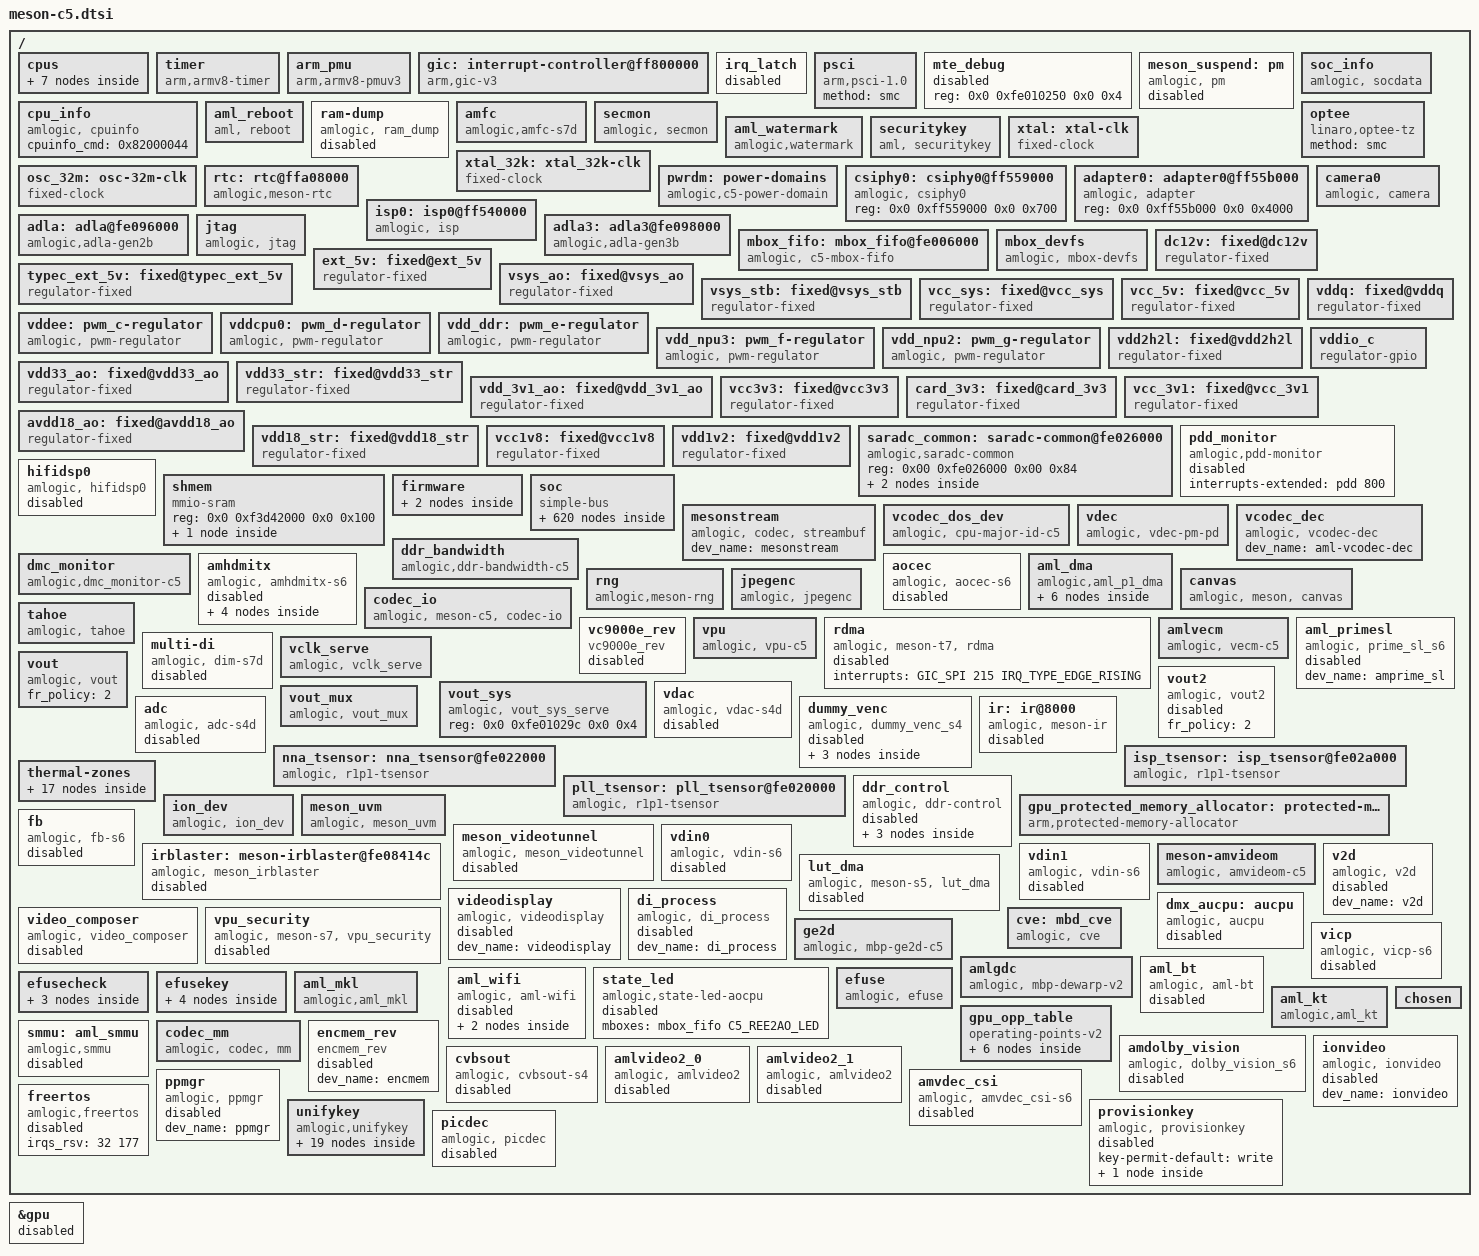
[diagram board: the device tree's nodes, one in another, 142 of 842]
// SPDX-License-Identifier: (GPL-2.0+ OR MIT)
/*
 * Copyright (c) 2019 Amlogic, Inc. All rights reserved.
 */

#include <dt-bindings/clock/axg-audio-clkc.h>
#include <dt-bindings/clock/amlogic,c5-clkc.h>
#include <dt-bindings/clock/amlogic,c5-scmi-clkc.h>
#include <dt-bindings/clock/g12a-aoclkc.h>
#include <dt-bindings/interrupt-controller/irq.h>
#include <dt-bindings/interrupt-controller/arm-gic.h>
#include <dt-bindings/power/c5-pd.h>
#include <dt-bindings/gpio/gpio.h>
#include <dt-bindings/gpio/meson-c5-gpio.h>
#include <dt-bindings/reset/amlogic,meson-c5-reset.h>
#include <dt-bindings/pwm/pwm.h>
#include <dt-bindings/pwm/meson.h>
#include <dt-bindings/input/input.h>
#include <dt-bindings/input/meson_ir.h>
#include <dt-bindings/mailbox/amlogic,mbox.h>
#include <dt-bindings/firmware/amlogic,firmware.h>
#include <dt-bindings/mailbox/c5-mbox.h>
#include <dt-bindings/iio/adc/amlogic-saradc.h>
#include <dt-bindings/thermal/ddr-params.h>
#include "meson-ir-map.dtsi"
#include "meson-valhall.dtsi"
/ {
	cpus:cpus {
		#address-cells = <2>;
		#size-cells = <0>;

		CPU0:cpu@0 {
			device_type = "cpu";
			compatible = "arm,cortex-a320","arm,armv9";
			reg = <0x0 0x0>;
			enable-method = "psci";
			cpu-idle-states = <&CPU_SLEEP_0 &SYSTEM_SLEEP_0>;
			dynamic-power-coefficient = <230>;
			#cooling-cells = <2>;
		};

		CPU1:cpu@1 {
			device_type = "cpu";
			compatible = "arm,cortex-a320","arm,armv9";
			reg = <0x0 0x100>;
			enable-method = "psci";
			cpu-idle-states = <&CPU_SLEEP_0 &SYSTEM_SLEEP_0>;
			dynamic-power-coefficient = <230>;
			#cooling-cells = <2>;
		};

		CPU2:cpu@2 {
			device_type = "cpu";
			compatible = "arm,cortex-a320","arm,armv9";
			reg = <0x0 0x200>;
			enable-method = "psci";
			cpu-idle-states = <&CPU_SLEEP_0 &SYSTEM_SLEEP_0>;
			dynamic-power-coefficient = <230>;
			#cooling-cells = <2>;
		};

		CPU3:cpu@3 {
			device_type = "cpu";
			compatible = "arm,cortex-a320","arm,armv9";
			reg = <0x0 0x300>;
			enable-method = "psci";
			cpu-idle-states = <&CPU_SLEEP_0 &SYSTEM_SLEEP_0>;
			dynamic-power-coefficient = <230>;
			#cooling-cells = <2>;
		};
		idle-states {
			entry-method = "arm,psci-0.2";
			CPU_SLEEP_0: cpu-sleep-0 {
					/*compatible = "arm,idle-state";*/
					arm,psci-suspend-param = <0x0010000>;
					local-timer-stop;
					entry-latency-us = <100>;
					exit-latency-us = <234>;
					min-residency-us = <1212>;
			};
			SYSTEM_SLEEP_0: system-sleep-0 {
					/*compatible = "arm,idle-state";*/
					arm,psci-suspend-param = <0x0000000>;
					entry-latency-us = <0x3fffffff>;
					exit-latency-us = <0x40000000>;
					min-residency-us = <0xffffffff>;
			};
		};
	};

	timer {
		compatible = "arm,armv8-timer";
		interrupts = <GIC_PPI 13 0xff08>,
				<GIC_PPI 14 0xff08>,
				<GIC_PPI 11 0xff08>,
				<GIC_PPI 10 0xff08>;
	};

	arm_pmu {
		compatible = "arm,armv8-pmuv3";
		/*private-interrupts;*/

		interrupts = <GIC_SPI 300 IRQ_TYPE_LEVEL_HIGH>,
				<GIC_SPI 301 IRQ_TYPE_LEVEL_HIGH>,
				<GIC_SPI 302 IRQ_TYPE_LEVEL_HIGH>,
				<GIC_SPI 303 IRQ_TYPE_LEVEL_HIGH>;
	};

	gic: interrupt-controller@ff800000 {
		compatible = "arm,gic-v3";
		#interrupt-cells = <3>;
		#address-cells = <0>;
		interrupt-controller;
		reg = <0x0 0xff800000 0 0x10000>,
		      <0x0 0xff840000 0 0x80000>;
		interrupts = <GIC_PPI 9 0xf04>;
	};

	irq_latch {
		/* only for GICv3 */
		status = "disabled";
		reg = <0x0 0xfe00a140 0x0 0x30>, /*mode*/
			<0x0 0xfe00a1c0 0x0 0x30>; /*latch clear*/
	};

	psci {
		compatible = "arm,psci-1.0";
		method = "smc";
	};

	mte_debug {
		status = "disabled";
		reg = <0x0 0xfe010250 0x0 0x4>; /*SYSCTRL_DEBUG_REG4*/
	};

	meson_suspend:pm {
		compatible = "amlogic, pm";
		status = "disabled";
		device_name = "aml_pm";
		extend_resume_reason;
		clear_suspend_reason = <9>; /* Clear netflix wakeup reason */
		reg = <0x0 0xfe010288 0x0 0x4>, /*SYSCTRL_STATUS_REG2*/
			<0x0 0xfe0102dc 0x0 0x4>; /*SYSCTRL_STICKY_REG7*/
	};

	cpu_info {
		compatible = "amlogic, cpuinfo";
		status = "okay";
		cpuinfo_cmd = <0x82000044>;
	};

	soc_info {
		compatible = "amlogic, socdata";
		reg =	<0x0 0xfe010000 0x0 0xc>,
			<0x0 0xfe010180 0x0 0x4>;
		read_nocsdata_cmd =<0x82000039>;
		write_nocsdata_cmd=<0x82000038>;
		auth_reg_ops_cmd=<0x820000f0>;
	};

	aml_reboot {
		compatible = "aml, reboot";
		sys_reset = <0x84000009>;
		sys_poweroff = <0x84000008>;
		dis_nb_cpus_in_shutdown;
		extend_reboot_reason; /* Support up to 128 reboot reasons*/
		reg = <0x0 0xfe01037c 0x0 0x4>; /* SEC_AO_SEC_SD_CFG15 */
		status = "okay";
	};

	ram-dump {
		compatible = "amlogic, ram_dump";
		status = "disabled";
		reg = <0x0 0xFE0102D8 0x0 4>;
		reg-names = "SYSCTRL_STICKY_REG6";
		store_device = "data";
	};

	amfc {
		compatible = "amlogic,amfc-s7d";
		status = "okay";
		/* registers and clk */
		reg = <0x0 0xfe024000 0x0 0x200
		       0x0 0xfe000000 0x0 0x400>;
		interrupts = <0 185 IRQ_TYPE_EDGE_RISING
			      0 186 IRQ_TYPE_EDGE_RISING>;
		interrupt-names = "amfc0", "amfc1";
		power-domains=<&pwrdm PDID_C5_AMFC>;
		clocks = <&clkc CLKID_AMFC>;
		assigned-clocks = <&clkc CLKID_AMFC>;
		assigned-clock-rates = <666666666>;
	};

	secmon:secmon {
		compatible = "amlogic, secmon";
		memory-region = <&secmon_reserved>;
		in_base_func = <0x82000020>;
		out_base_func = <0x82000021>;
		inout_size_func = <0x8200002a>;
		reserve_mem_size = <0x03300000>;
	};

	optee {
		compatible = "linaro,optee-tz";
		method = "smc";
	};

	aml_watermark {
		compatible = "amlogic,watermark";
		soc-name = "s6";
		interrupts = <GIC_SPI 197 IRQ_TYPE_EDGE_RISING>; //=viu-vsync
		interrupt-names = "wm-vsync";
	};

	securitykey {
		compatible = "aml, securitykey";
		storage_query = <0x82000060>;
		storage_read = <0x82000061>;
		storage_write = <0x82000062>;
		storage_tell = <0x82000063>;
		storage_verify = <0x82000064>;
		storage_status = <0x82000065>;
		storage_list = <0x82000067>;
		storage_remove = <0x82000068>;
		storage_in_func = <0x82000023>;
		storage_out_func = <0x82000024>;
		storage_block_func = <0x82000025>;
		storage_size_func = <0x82000027>;
		storage_set_enctype = <0x8200006A>;
		storage_get_enctype = <0x8200006B>;
		storage_version = <0x8200006C>;
	};

	xtal: xtal-clk {
		compatible = "fixed-clock";
		clock-frequency = <24000000>;
		clock-output-names = "xtal";
		#clock-cells = <0>;
	};

	xtal_32k: xtal_32k-clk {
		compatible = "fixed-clock";
		clock-frequency = <32768>;
		clock-output-names = "xtal_32k";
		#clock-cells = <0>;
	};

	osc_32m: osc-32m-clk {
		compatible = "fixed-clock";
		clock-frequency = <32000000>;
		clock-output-names = "osc_32m";
		#clock-cells = <0>;
	};

	rtc: rtc@ffa08000 {
		compatible = "amlogic,meson-rtc";
		reg = <0x0 0xffa08000 0x0 0x38>;
		interrupts = <GIC_SPI 404 IRQ_TYPE_EDGE_RISING>;
		clocks = <&ao_clkc CLKID_AO_OSCIN32K_CLK>,
			 <&ao_clkc CLKID_AO_SYS_RTC_DIG>;
		clock-names = "osc", "sys";
		time-storage-format-gray;
		status = "okay";
		assigned-clocks = <&ao_clkc CLKID_AO_OSCIN32K_CLK>;
		assigned-clock-parents = <&xtal_32k>;
	};

	pwrdm: power-domains {
		compatible = "amlogic,c5-power-domain";
		#power-domain-cells = <1>;
		status = "okay";
	};

	csiphy0: csiphy0@ff559000 {
		compatible = "amlogic, csiphy0";
		reg = <0x0 0xff559000 0x0 0x700>;
		//clocks = <&clkc CLKID_CSIPHY0>;
		clock-names = "mipi_phy_clk";
		reg-names = "csi_phy0";
		status = "okay";
	};

	adapter0: adapter0@ff55b000 {
		compatible = "amlogic, adapter";
		reg = <0x0 0xff55b000 0x0 0x4000>;
		reg-names = "adapter";
		status = "okay";
	};

	isp0: isp0@ff540000 {
		compatible = "amlogic, isp";
		reg = <0x0 0xff540000 0x0 0x17780>,
				<0x0 0xff566000 0x0 0x600>;
		reg-names = "base", "disp";
		power-domains = <&pwrdm PDID_C5_ISP>,<&pwrdm PDID_C5_DEWARP>;
		power-domain-names = "isp_pd", "opp_pd";
		clocks = <&clkc CLKID_CSIPHY0>, <&clkc CLKID_ISP0>, <&clkc CLKID_DEWARPA>;
		clock-names = "mipi_csi_clk", "mipi_isp_clk", "isp_dewarp_clk";
		interrupts = <GIC_SPI 383 IRQ_TYPE_EDGE_RISING>,
			     <GIC_SPI 372 IRQ_TYPE_EDGE_RISING>,
			     <GIC_SPI 373 IRQ_TYPE_EDGE_RISING>,
			     <GIC_SPI 374 IRQ_TYPE_EDGE_RISING>,
			     <GIC_SPI 379 IRQ_TYPE_EDGE_RISING>,
			     <GIC_SPI 380 IRQ_TYPE_EDGE_RISING>;
		interrupt-names = "fe_rst", "fe_done", "be_done",
				  "opp_done", "mipi_top", "intf";
		status = "okay";
	};

	camera0 {
		compatible = "amlogic, camera";
		index = <0>;
		csiphy = <&csiphy0>;
		adapter = <&adapter0>;
		isp = <&isp0>;
		status = "okay";
	};

	adla: adla@fe096000 {
		compatible = "amlogic,adla-gen2b";
		dev_name = "adla";
		status = "okay";
		reg = <0x0 0xfe096000 0x0 0x2000
			0x0 0xf3d00000 0x0 0x15FFFF
			>;
		reg-names = "adla_reg\0adla_sram";
		interrupt-names = "adla";
		interrupts = <GIC_SPI 258 IRQ_TYPE_LEVEL_HIGH>;
		clocks = <&clkc CLKID_NNA2_CORE>;
		clock-names = "adla_core_clk";
		power-domains=<&pwrdm PDID_C5_NNA2>;
		nn_hw_version="r3p3";
		adla_core_clk_rate = <1000000000>;
		adla_smc_cmd = <0x820000b2>;
		smmu;
	};

	adla3: adla3@fe098000 {
		compatible = "amlogic,adla-gen3b";
		dev_name = "adla";
		status = "okay";
		reg = <0x0 0xfe098000 0x0 0x2000
			0x0 0xf3d00000 0x0 0x15FFFF
			>;
		reg-names = "adla_reg\0adla_sram";
		interrupt-names = "adla";
		interrupts = <GIC_SPI 260 IRQ_TYPE_LEVEL_HIGH>;
		clocks = <&clkc CLKID_NNA_CORE>;
		clock-names = "adla_core_clk";
		power-domains=<&pwrdm PDID_C5_NNA3>;
		nn_hw_version="r4p2";
		adla_core_clk_rate = <1000000000>;
		adla_smc_cmd = <0x820000b2>;
		smmu;
	};

	jtag {
		compatible = "amlogic, jtag";
		status = "okay";
		select = "disable"; /* disable/jtag_a/jtag_b */
		pinctrl-names="jtag_a_pins", "jtag_b_pins";
		pinctrl-0=<&jtag_a_pins>;
		pinctrl-1=<&jtag_b_pins>;
	};

	mbox_fifo: mbox_fifo@fe006000 {
		status = "okay";
		compatible = "amlogic, c5-mbox-fifo";
		reg = <0x0 0xfe006000 0x0 0x800>,  /* mbox wr fifo */
		      <0x0 0xfe006800 0x0 0x800>,  /* mbox rd fifo */
		      <0x0 0xfe0070c0 0x0 0x40>,   /* mbox set reg */
		      <0x0 0xfe007100 0x0 0x40>,   /* mbox clr reg */
		      <0x0 0xfe007140 0x0 0x40>,   /* mbox sts reg */
		      <0x0 0xfe007020 0x0 0x40>;   /* mbox irqctrl reg */
		interrupts = <GIC_SPI 248 IRQ_TYPE_EDGE_RISING>;   /* mbox top irq */
		mbox-irqctlr = <0>;
		mbox-nums = <C5_MBOX_NUMS>;
		mboxids = <C5_MBOX_AO2REE>,
			  <C5_MBOX_REE2AO>;
		aocpu_sts_mboxid = <C5_MBOX_AO2TEE>;
		ree2aocpu_mboxid = <C5_MBOX_REE2AO>;
		#mbox-cells = <1>;
	};

	mbox_devfs {
		status = "okay";
		compatible = "amlogic, mbox-devfs";
		mbox-nums = <2>;
		mbox-names = "ree2aocpu",
			     "aocpu2ree";
		mboxes = <&mbox_fifo C5_REE2AO_DEV>,
			 <&mbox_fifo C5_AO2REE_DEV>;
		mbox-dests = <MAILBOX_AOCPU>,
			     <MAILBOX_ARM>;
	};

	dc12v: fixed@dc12v {
		compatible = "regulator-fixed";
		regulator-name = "DC12V";
		regulator-min-microvolt = <12000000>;
		regulator-max-microvolt = <12000000>;
		regulator-boot-on;
		regulator-always-on;
	};

	ext_5v: fixed@ext_5v { //to charger ic
		compatible = "regulator-fixed";
		vin-supply = <&dc12v>;
		regulator-name = "EXT_5V";
		regulator-min-microvolt = <5000000>;
		regulator-max-microvolt = <5000000>;
		regulator-boot-on;
		regulator-always-on;
	};

	typec_ext_5v: fixed@typec_ext_5v {
		compatible = "regulator-fixed";
		vin-supply = <&ext_5v>;
		regulator-name = "TYPEC_5V_EXT";
		regulator-min-microvolt = <5000000>;
		regulator-max-microvolt = <5000000>;
		regulator-boot-on;
		regulator-always-on;
	};

	vsys_ao: fixed@vsys_ao { //charger ic out
		compatible = "regulator-fixed";
		vin-supply = <&ext_5v>;
		regulator-name = "VSYS_AO";
		regulator-min-microvolt = <5000000>;
		regulator-max-microvolt = <5000000>;
		regulator-boot-on;
		regulator-always-on;
	};

	//Power ON/OFF for Debug Test
	vsys_stb: fixed@vsys_stb { //Slide_Switch_PWR
		compatible = "regulator-fixed";
		vin-supply = <&vsys_ao>;
		regulator-name = "VSYS_STB";
		regulator-min-microvolt = <5000000>;
		regulator-max-microvolt = <5000000>;
		regulator-boot-on;
		regulator-always-on;
	};

	vcc_sys: fixed@vcc_sys {
		compatible = "regulator-fixed";
		vin-supply = <&vsys_stb>;
		regulator-name = "VCC_SYS";
		regulator-min-microvolt = <5000000>;
		regulator-max-microvolt = <5000000>;
		//PWR_UP to PWR_EE_CTRL
		gpio = <&gpio_ao GPIOAO_24 GPIO_ACTIVE_HIGH>;
		startup-delay-us = <7000>;
		enable-active-high;
		regulator-boot-on;
		regulator-always-on;
	};

	vcc_5v: fixed@vcc_5v {
		compatible = "regulator-fixed";
		vin-supply = <&vcc_sys>;
		regulator-name = "Boost VCC_5V";
		regulator-min-microvolt = <5000000>;
		regulator-max-microvolt = <5000000>;
		regulator-boot-on;
		regulator-always-on;
	};

	vddee: pwm_c-regulator {
		compatible = "amlogic, pwm-regulator";
		vin-supply = <&vcc_sys>;
		pwms = <&pwm_c MESON_PWM_0 630 0>;//GPIOE_0
		regulator-name = "VDD_EE";
		regulator-min-microvolt = <680000>;
		regulator-max-microvolt = <830000>;
		regulator-always-on;
		max-duty-cycle = <630>;
		amlogic,vsel-step = <3>;
		amlogic,usleep-time = <200>;
		amlogic,udelay-time = <40 20>;//pwm 1nF
		/* Voltage Duty-Cycle */
		voltage-table = <830000 0>,
				<820000 7>,
				<810000 13>,
				<800000 20>,
				<790000 27>,
				<780000 33>,
				<770000 40>,
				<760000 47>,
				<750000 53>,
				<740000 60>,
				<730000 67>,
				<720000 73>,
				<710000 80>,
				<700000 87>,
				<690000 93>,
				<680000 100>;
		status = "okay";
	};

	vddcpu0: pwm_d-regulator {
		compatible = "amlogic, pwm-regulator";
		vin-supply = <&vcc_sys>;
		pwms = <&pwm_d MESON_PWM_0 1260 0>;//GPIOE_1
		regulator-name = "VDDCPU_A320";
		regulator-min-microvolt = <680000>;
		regulator-max-microvolt = <980000>;
		regulator-always-on;
		max-duty-cycle = <1260>;
		amlogic,vsel-step = <3>;
		amlogic,usleep-time = <200>;
		amlogic,udelay-time = <40 20>;	//pwm 1nF
		/* Voltage Duty-Cycle */
		voltage-table = <980000 0>,
				<970000 3>,
				<960000 7>,
				<950000 10>,
				<940000 13>,
				<930000 17>,
				<920000 20>,
				<910000 23>,
				<900000 27>,
				<890000 30>,
				<880000 33>,
				<870000 37>,
				<860000 40>,
				<850000 43>,
				<840000 47>,
				<830000 50>,
				<820000 53>,
				<810000 57>,
				<800000 60>,
				<790000 63>,
				<780000 67>,
				<770000 70>,
				<760000 73>,
				<750000 77>,
				<740000 80>,
				<730000 83>,
				<720000 87>,
				<710000 90>,
				<700000 93>,
				<690000 97>,
				<680000 100>;
		status = "okay";
	};

	vdd_ddr: pwm_e-regulator {
		compatible = "amlogic, pwm-regulator";
		vin-supply = <&vcc_sys>;
		pwms = <&pwm_e MESON_PWM_0 630 0>;//GPIOE_2
		regulator-name = "VDD_DDR";
		regulator-min-microvolt = <680000>;
		regulator-max-microvolt = <830000>;
		regulator-always-on;
		max-duty-cycle = <630>;
		amlogic,vsel-step = <3>;
		amlogic,usleep-time = <200>;
		amlogic,udelay-time = <40 20>;//pwm 1nF
		/* Voltage Duty-Cycle */
		voltage-table = <830000 0>,
				<820000 7>,
				<810000 13>,
				<800000 20>,
				<790000 27>,
				<780000 33>,
				<770000 40>,
				<760000 47>,
				<750000 53>,
				<740000 60>,
				<730000 67>,
				<720000 73>,
				<710000 80>,
				<700000 87>,
				<690000 93>,
				<680000 100>;
		status = "okay";
	};

	vdd_npu3: pwm_f-regulator {
		compatible = "amlogic, pwm-regulator";
		vin-supply = <&vcc_sys>;
		pwms = <&pwm_f MESON_PWM_0 840 0>;//GPIOE_3
		regulator-name = "VDD_NPU3";
		regulator-min-microvolt = <660000>;
		regulator-max-microvolt = <860000>;
		regulator-always-on;
		max-duty-cycle = <840>;
		amlogic,vsel-step = <3>;
		amlogic,usleep-time = <200>;
		amlogic,udelay-time = <40 20>;//pwm 1nF
		/* Voltage Duty-Cycle */
		voltage-table = <860000 0>,
				<850000 5>,
				<840000 10>,
				<830000 15>,
				<820000 20>,
				<810000 25>,
				<800000 30>,
				<790000 35>,
				<780000 40>,
				<770000 45>,
				<760000 50>,
				<750000 55>,
				<740000 60>,
				<730000 65>,
				<720000 70>,
				<710000 75>,
				<700000 80>,
				<690000 85>,
				<680000 90>,
				<670000 95>,
				<660000 100>;
		status = "okay";
	};

	vdd_npu2: pwm_g-regulator {
		compatible = "amlogic, pwm-regulator";
		vin-supply = <&vcc_sys>;
		pwms = <&pwm_g MESON_PWM_0 840 0>;//GPIOE_4
		regulator-name = "VDD_NPU2";
		regulator-min-microvolt = <660000>;
		regulator-max-microvolt = <860000>;
		regulator-always-on;
		max-duty-cycle = <840>;
		amlogic,vsel-step = <3>;
		amlogic,usleep-time = <200>;
		amlogic,udelay-time = <40 20>;//pwm 1nF
		/* Voltage Duty-Cycle */
		voltage-table = <860000 0>,
				<850000 5>,
				<840000 10>,
				<830000 15>,
				<820000 20>,
				<810000 25>,
				<800000 30>,
				<790000 35>,
				<780000 40>,
				<770000 45>,
				<760000 50>,
				<750000 55>,
				<740000 60>,
				<730000 65>,
				<720000 70>,
				<710000 75>,
				<700000 80>,
				<690000 85>,
				<680000 90>,
				<670000 95>,
				<660000 100>;
		status = "okay";
	};

	vddq: fixed@vddq { //Option
		compatible = "regulator-fixed";
		vin-supply = <&vsys_stb>;
		regulator-name = "VDDQ";
		regulator-min-microvolt = <500000>;
		regulator-max-microvolt = <500000>;
		//STR_EN
		gpio = <&gpio_ao GPIOAO_16 GPIO_ACTIVE_HIGH>;
		startup-delay-us = <7000>;
		enable-active-high;
		regulator-boot-on;
		regulator-always-on;
	};

	vdd2h2l: fixed@vdd2h2l { //Option
		compatible = "regulator-fixed";
		vin-supply = <&vsys_stb>;
		regulator-name = "VDD2H/VDD2L";
		regulator-min-microvolt = <1050000>;
		regulator-max-microvolt = <1050000>;
		//STR_EN
		gpio = <&gpio_ao GPIOAO_16 GPIO_ACTIVE_HIGH>;
		startup-delay-us = <7000>;
		enable-active-high;
		regulator-boot-on;
		regulator-always-on;
	};

	vdd33_ao: fixed@vdd33_ao {
		compatible = "regulator-fixed";
		vin-supply = <&vsys_stb>;
		regulator-name = "VDD33_AO";
		regulator-min-microvolt = <3300000>;
		regulator-max-microvolt = <3300000>;
		regulator-boot-on;
		regulator-always-on;
	};

	vdd33_str: fixed@vdd33_str { //Only needed in the AOV camera scenario.
		compatible = "regulator-fixed";
		vin-supply = <&vdd33_ao>;
		regulator-name = "VDD33_STR";
		regulator-min-microvolt = <3300000>;
		regulator-max-microvolt = <3300000>;
		//STR_EN
		gpio = <&gpio_ao GPIOAO_16 GPIO_ACTIVE_HIGH>;
		startup-delay-us = <7000>;
		enable-active-high;
		regulator-boot-on;
		regulator-always-on;
	};

	vdd_3v1_ao: fixed@vdd_3v1_ao { //Option 3.1V
		compatible = "regulator-fixed";
		vin-supply = <&vdd33_ao>;
		regulator-name = "VDD_3V1_AO";
		regulator-min-microvolt = <3100000>;
		regulator-max-microvolt = <3100000>;
		regulator-boot-on;
		regulator-always-on;
	};

	vcc3v3: fixed@vcc3v3 {
		compatible = "regulator-fixed";
		vin-supply = <&vdd33_ao>;
		regulator-name = "VCC3V3";
		regulator-min-microvolt = <3300000>;
		regulator-max-microvolt = <3300000>;
		//VDD33_CTRL
		gpio = <&gpio_ao GPIOAO_25 GPIO_ACTIVE_HIGH>;
		startup-delay-us = <7000>;
		enable-active-high;
		regulator-boot-on;
		regulator-always-on;
	};

	card_3v3: fixed@card_3v3 {
		compatible = "regulator-fixed";
		vin-supply = <&vcc3v3>;
		regulator-name = "3V3_CARD";
		regulator-min-microvolt = <3300000>;
		regulator-max-microvolt = <3300000>;
		//SD_PWR_EN
		gpio = <&gpio GPIOC_7 (GPIO_ACTIVE_HIGH | GPIO_OPEN_DRAIN)>;
		startup-delay-us = <7000>;
		enable-active-high;
		regulator-boot-on;
		regulator-always-on;
	};

	vddio_c: vddio_c {
		compatible = "regulator-gpio";
		vin-supply = <&vcc3v3>;
		regulator-name = "VDDIO_C";
		regulator-min-microvolt = <1800000>;
		regulator-max-microvolt = <3300000>;
		//L=3.3V H=1.8V (GPIOE_6 (HiZ)(PWM_I))
		gpio = <&gpio GPIOE_6 GPIO_ACTIVE_HIGH>;
		gpios-states = <0>;
		states = <1800000 1 3300000 0>;
		startup-delay-us = <7000>;
		regulator-boot-on;
		//regulator-always-on;
	};

	vcc_3v1: fixed@vcc_3v1 { //Option 3.1V
		compatible = "regulator-fixed";
		vin-supply = <&vcc3v3>;
		regulator-name = "VCC_3V1";
		regulator-min-microvolt = <3100000>;
		regulator-max-microvolt = <3100000>;
		regulator-boot-on;
		regulator-always-on;
	};

	avdd18_ao: fixed@avdd18_ao {
		compatible = "regulator-fixed";
		vin-supply = <&vsys_stb>;
		regulator-name = "AVDD18_AO";
		regulator-min-microvolt = <1800000>;
		regulator-max-microvolt = <1800000>;
		regulator-boot-on;
		regulator-always-on;
	};

	vdd18_str: fixed@vdd18_str { //Only needed in the AOV camera scenario.
		compatible = "regulator-fixed";
		vin-supply = <&avdd18_ao>;
		regulator-name = "VDD18_STR";
		regulator-min-microvolt = <1800000>;
		regulator-max-microvolt = <1800000>;
		//STR_EN
		gpio = <&gpio_ao GPIOAO_16 GPIO_ACTIVE_HIGH>;
		startup-delay-us = <7000>;
		enable-active-high;
		regulator-boot-on;
		regulator-always-on;
	};

	vcc1v8: fixed@vcc1v8 {
		compatible = "regulator-fixed";
		vin-supply = <&avdd18_ao>;
		regulator-name = "VCC1V8";
		regulator-min-microvolt = <1800000>;
		regulator-max-microvolt = <1800000>;
		//VDD18_CTRL
		gpio = <&gpio_ao GPIOAO_23 GPIO_ACTIVE_HIGH>;
		startup-delay-us = <7000>;
		enable-active-high;
		regulator-boot-on;
		regulator-always-on;
	};

	vdd1v2: fixed@vdd1v2 { //Option: Removable if Not use PSRAM
		compatible = "regulator-fixed";
		vin-supply = <&vsys_stb>;
		regulator-name = "VDD1V2";
		regulator-min-microvolt = <1200000>;
		regulator-max-microvolt = <1200000>;
		regulator-boot-on;
		regulator-always-on;
	};

	saradc_common: saradc-common@fe026000 {
		compatible = "amlogic,saradc-common";
		reg = <0x00 0xfe026000 0x00 0x84>;

		saradc: saradc {
			compatible = "amlogic,saradc", "amlogic,s7d-saradc";
			interrupts = <GIC_SPI 181 IRQ_TYPE_EDGE_RISING>;
			//clock-names = "src", "core", "gate", "mux";
			//clocks = <&xtal>,
			//	 <&clkc CLKID_SYS_SAR_ADC>,
			//	 <&clkc CLKID_SAR_ADC>,
			//	 <&clkc CLKID_SAR_ADC_MUX>;
			#io-channel-cells = <1>;
			amlogic,clock-frequency = <3000000>;
			amlogic,test-channel = <7>;
			amlogic,fifo-data-width = <16>;
			/* Filter control */
			amlogic,reg7-init = <0x00000c11>;
			amlogic,reg8-init = <0x0280614d>;
			/* Delay configure */
			amlogic,reg3-init = <0x10a02403>;
			amlogic,reg4-init = <0x001dd080>;
			/* Set aux and external vref */
			amlogic,reg9-init = <0x0000f0f0>;
			amlogic,reg10-init = <0x70503010>;
			amlogic,reg11-init = <0xf0d0b090>;
			reset-names = "analog";
			//resets = <&reset RESET_SAR_ANA>;
			status = "disabled";
		};

		pdd: pdd {
			compatible = "amlogic,pdd";
			interrupt-controller;
			#interrupt-cells = <1>;
			//clock-names = "core";
			//clocks = <&clkc CLKID_SYS_SAR_ADC>;
			amlogic,interrupt = <182>;
			amlogic,digital-maps = <0x18 26>, <0x18 23>, <0x18 17>,
					       <0x18 12>, <0x18 14>;
			amlogic,analog-maps = <0x14 26>, <0x14 22>, <0x14 24>;
			amlogic,voltage-maps = <400>, <800>, <800>, <1200>;
			status = "disabled";
		};
	};

	pdd_monitor {
		compatible = "amlogic,pdd-monitor";
		/* Trigger threshold voltage: 800 mV */
		interrupts-extended = <&pdd 800>;
		status = "disabled";
	};

	hifidsp0: hifidsp0 {
		compatible = "amlogic, hifidsp0";
		status = "disabled";
		startup-position = /bits/ 8 <PURE_DDR>; /*host dsp start mode : DDR*/
		memory-region = <&dsp_fw_reserved>;
		reg-names = "base-reg",
			    "health-reg",
			    "device-support-reg",
			    "ddrfw-region",
			    "shm-region";
		reg = <0x0 0xfe380000 0x0 0x114>, /*host base address*/
		      <0x0 0xfe010258 0x0 0x4>, /*host health reg address*/
		      <0x0 0xfe44006c 0x0 0x4>, /*dsp support region*/
		      <0x0 0x0 0x0 0x800000>, /*host ddrfw region [offset size]*/
		      <0x0 0x780000 0x0 0x80000>; /*host shm region [offset size]*/
		//assigned-clocks = <&scmi_clk CLKID_GP2_PLL>;
		//assigned-clock-rates = <1002000000>;
		//clocks = <&clkc CLKID_DSPA>,
		//	 <&clkc CLKID_HIFI_PLL>;
		//clock-names = "dspa_clk",
		//	      "dspa_clk_hifi";
		/* host dsp support bit
		 * efuse reg OTP_LIC23 bit[24]
		 * 1: disable
		 * 0: enable
		 */
		dsp-support-bit = <0x1000000>;
		/* bit0: pm_support_suspend
		 * bit1: pm_support_always_on
		 * bit2: pm_support_ffv
		 */
		pm-support = /bits/ 8 <0x5>;
		//power-domains = <&pwrdm PDID_S6_DSPA>;
		power-domain-names = "dspa";
		mboxes = <&mbox_fifo C5_REE2DSPA_HOST>,
			 <&mbox_fifo C5_DSPA2REE_HOST>;
		//logbuff-polling-ms = <50>;
		health-polling-ms = <1000>;
		clkfreq-khz = <1002000>;
	};

	shmem {
		compatible = "mmio-sram";
		reg = <0x0 0xf3d42000 0x0 0x100>;
		#address-cells = <1>;
		#size-cells = <1>;
		ranges = <0 0x0 0xf3d42000 0x100>;

		scmi_shmem: shmem@0 {
			compatible = "arm,scmi-shmem";
			reg = <0x0 0x100>;
		};
	};

	firmware {
		scmi: scmi {
			compatible = "arm,scmi-smc";
			arm,smc-id = <0x820000C1>;
			shmem = <&scmi_shmem>;
			#address-cells = <1>;
			#size-cells = <0>;

			scmi_clk: protocol@14 {
				reg = <0x14>;
				#clock-cells = <1>;
			};
		};
	};

	soc {
		compatible = "simple-bus";
		#address-cells = <2>;
		#size-cells = <2>;
		ranges;

		apb4: apb4@fe000000 {
			compatible = "simple-bus";
			reg = <0x0 0xfe000000 0x0 0x480000>;
			#address-cells = <2>;
			#size-cells = <2>;
			ranges = <0x0 0x0 0x0 0xfe000000 0x0 0x480000>;

			clkc: clock-controller@0 {
				compatible = "amlogic,c5-clkc";
				#clock-cells = <1>;
				reg = <0x0 0x0 0x0 0x4a0>,
				      <0x0 0x8000 0x0 0x38c>;
				reg-names = "basic", "pll";
				clocks = <&xtal>,
					 <&scmi_clk CLKID_GP0_PLL_OSC>,
					 <&scmi_clk CLKID_HIFI_PLL_OSC>,
					 <&scmi_clk CLKID_DSI_PLL_OSC>,
					 <&scmi_clk CLKID_FIXED_PLL>,
					 <&scmi_clk CLKID_SYS_CLK>,
					 <&scmi_clk CLKID_AXI_CLK>,
					 <&scmi_clk CLKID_SYS_PLL_DIV16>,
					 <&scmi_clk CLKID_CPU_CLK_DIV16>;
				clock-names = "xtal",
					      "gp0_pll_osc",
					      "hifi_pll_osc",
					      "dsi_pll_osc",
					      "fixed_pll",
					      "sys_clk",
					      "axi_clk",
					      "sys_pll_div16",
					      "cpu_clk_div16";
				status = "okay";
			};

			meson_clk_msr@48000 {
				compatible = "amlogic,meson-c5-clk-measure";
				reg = <0x0 0x48000 0x0 0x1c>;
			};

			watchdog@2100 {
				compatible = "amlogic,meson-sc2-wdt";
				/* 0:userspace, 1:kernel */
				amlogic,feed_watchdog_mode = <1>;
				reg = <0x0 0x2100 0x0 0x10>;
				clocks = <&xtal>;
			};

			periphs_pinctrl: pinctrl@4000 {
				compatible = "amlogic,meson-c5-periphs-pinctrl";
				#address-cells = <2>;
				#size-cells = <2>;
				ranges;

				gpio: bank@4000 {
					reg = <0x0 0x4000 0x0 0x004c>,
					      <0x0 0x40c0 0x0 0x0260>;
					reg-names = "mux", "gpio";
					gpio-controller;
					#gpio-cells = <2>;
					gpio-ranges = <&periphs_pinctrl 0 0 109>;
				};
			};

			gpio_intc: interrupt-controller@4080 {
				compatible = "amlogic,meson-c5-gpio-intc",
					     "amlogic,meson-gpio-intc";
				reg = <0x0 0x4080 0x0 0x20>;
				interrupt-controller;
				#interrupt-cells = <2>;
				amlogic,channel-interrupts =
					<10 11 12 13 14 15 16 17 18 19 20 21>;
			};

			spisg_b: spi@50000 {
				compatible = "amlogic,meson-t6x-spicc-v2";
				reg = <0x0 0x50000 0x0 0x38>;
				interrupts = <GIC_SPI 183 IRQ_TYPE_LEVEL_HIGH>;
				clocks = <&clkc CLKID_SYS_SPISG0>,
					 <&clkc CLKID_SPISG0>;
				clock-names = "sys", "spi";
				assigned-clocks = <&clkc CLKID_SPISG0>;
				assigned-clock-rates = <500000000>;
				#address-cells = <1>;
				#size-cells = <0>;
				status = "disabled";
			};

			spisg_c: spi@50100 {
				compatible = "amlogic,meson-t6x-spicc-v2";
				reg = <0x0 0x50100 0x0 0x38>;
				interrupts = <GIC_SPI 184 IRQ_TYPE_LEVEL_HIGH>;
				clocks = <&clkc CLKID_SYS_SPISG0>,
					 <&clkc CLKID_SPISG1>;
				clock-names = "sys", "spi";
				assigned-clocks = <&clkc CLKID_SPISG1>;
				assigned-clock-rates = <500000000>;
				#address-cells = <1>;
				#size-cells = <0>;
				status = "disabled";
			};

			spisg_d: spi@50200 {
				compatible = "amlogic,meson-t6x-spicc-v2";
				reg = <0x0 0x50200 0x0 0x38>;
				interrupts = <GIC_SPI 187 IRQ_TYPE_LEVEL_HIGH>;
				clocks = <&clkc CLKID_SYS_SPISG0>,
					 <&clkc CLKID_SPISG2>;
				clock-names = "sys", "spi";
				assigned-clocks = <&clkc CLKID_SPISG2>;
				assigned-clock-rates = <500000000>;
				#address-cells = <1>;
				#size-cells = <0>;
				status = "disabled";
			};

			spifc: spi@56000 {
				compatible = "amlogic,meson-spifc";
				status = "disabled";
				reg = <0x0 0x56000 0x0 0x80>;
				//clock-names = "default";
				//clocks = <&clkc CLKID_SPIFC>;
				pinctrl-names = "default";
				pinctrl-0 = <&spifc_pins>;
				#address-cells = <1>;
				#size-cells = <0>;
				spi-nor@0 {
					compatible = "jedec,spi-nor";
					status = "disabled";
					reg = <0>;
					spi-max-frequency = <16000000>;
				};
			};

			pwm_c: pwm@58000 {
				compatible = "amlogic,meson-pwm-tee";
				reg = <0x0  0x58000 0x0 0x24>;
				#pwm-cells = <3>;
				clocks = <&clkc CLKID_PWM_C>;
				clock-names = "clkin0";
				tee_id = <2>;
				status = "okay";
				pinctrl-names="default";
				pinctrl-0=<&pwm_c_pins1>;
			};

			pwm_d: pwm@58100 {
				compatible = "amlogic,meson-pwm-tee";
				reg = <0x0 0x58100 0x0 0x24>;
				#pwm-cells = <3>;
				clocks = <&clkc CLKID_PWM_D>;
				clock-names = "clkin0";
				tee_id = <3>;
				status = "okay";
				pinctrl-names="default";
				pinctrl-0=<&pwm_d_pins1>;
			};

			pwm_e: pwm@58200 {
				compatible = "amlogic,meson-pwm-tee";
				reg = <0x0 0x58200 0x0 0x24>;
				#pwm-cells = <3>;
				clocks = <&clkc CLKID_PWM_E>;
				clock-names = "clkin0";
				tee_id = <4>;
				status = "okay";
				pinctrl-names="default";
				pinctrl-0=<&pwm_e_pins1>;
			};

			pwm_f: pwm@58300 {
				compatible = "amlogic,meson-pwm-tee";
				reg = <0x0 0x58300 0x0 0x24>;
				#pwm-cells = <3>;
				clocks = <&clkc CLKID_PWM_F>;
				clock-names = "clkin0";
				tee_id = <5>;
				status = "okay";
				pinctrl-names="default";
				pinctrl-0=<&pwm_f_pins1>;
			};

			pwm_g: pwm@58400 {
				compatible = "amlogic,meson-pwm-tee";
				reg = <0x0  0x58400 0x0 0x24>;
				#pwm-cells = <3>;
				clocks = <&clkc CLKID_PWM_G>;
				clock-names = "clkin0";
				tee_id = <6>;
				status = "okay";
				pinctrl-names="default";
				pinctrl-0=<&pwm_g_pins1>;
			};

			pwm_h: pwm@58500 {
				compatible = "amlogic,meson-pwm-tee";
				reg = <0x0 0x58500 0x0 0x24>;
				#pwm-cells = <3>;
				clocks = <&clkc CLKID_PWM_H>;
				clock-names = "clkin0";
				tee_id = <7>;
				status = "okay";
				pinctrl-names="default";
				pinctrl-0=<&pwm_h_pins1>;
			};

			pwm_i: pwm@58600 {
				compatible = "amlogic,meson-pwm-tee";
				reg = <0x0 0x58600 0x0 0x24>;
				#pwm-cells = <3>;
				clocks = <&clkc CLKID_PWM_I>;
				clock-names = "clkin0";
				tee_id = <8>;
				status = "disabled";
			};

			pwm_j: pwm@58700 {
				compatible = "amlogic,meson-pwm-tee";
				reg = <0x0 0x58700 0x0 0x24>;
				#pwm-cells = <3>;
				clocks = <&clkc CLKID_PWM_J>;
				clock-names = "clkin0";
				tee_id = <9>;
				status = "okay";
				pinctrl-names="default";
				pinctrl-0=<&pwm_j_pins1>;
			};

			pwm_k: pwm@58800 {
				compatible = "amlogic,meson-pwm-tee";
				reg = <0x0  0x58800 0x0 0x24>;
				#pwm-cells = <3>;
				clocks = <&clkc CLKID_PWM_K>;
				clock-names = "clkin0";
				tee_id = <10>;
				status = "disabled";
			};

			pwm_l: pwm@58900 {
				compatible = "amlogic,meson-pwm-tee";
				reg = <0x0 0x58900 0x0 0x24>;
				#pwm-cells = <3>;
				clocks = <&clkc CLKID_PWM_L>;
				clock-names = "clkin0";
				tee_id = <11>;
				status = "disabled";
			};

			pwm_m: pwm@58a00 {
				compatible = "amlogic,meson-pwm-tee";
				reg = <0x0 0x58a00 0x0 0x24>;
				#pwm-cells = <3>;
				clocks = <&clkc CLKID_PWM_M>;
				clock-names = "clkin0";
				tee_id = <12>;
				status = "disabled";
			};

			pwm_n: pwm@58b00 {
				compatible = "amlogic,meson-pwm-tee";
				reg = <0x0 0x58b00 0x0 0x24>;
				#pwm-cells = <3>;
				clocks = <&clkc CLKID_PWM_N>;
				clock-names = "clkin0";
				tee_id = <13>;
				status = "disabled";
			};

			pwm_o: pwm@58c00 {
				compatible = "amlogic,meson-pwm-tee";
				reg = <0x0  0x58c00 0x0 0x24>;
				#pwm-cells = <3>;
				clocks = <&clkc CLKID_PWM_O>;
				clock-names = "clkin0";
				tee_id = <14>;
				status = "disabled";
			};

			pwm_p: pwm@58d00 {
				compatible = "amlogic,meson-pwm-tee";
				reg = <0x0 0x58d00 0x0 0x24>;
				#pwm-cells = <3>;
				clocks = <&clkc CLKID_PWM_P>;
				clock-names = "clkin0";
				tee_id = <15>;
				status = "disabled";
			};

			pwm_q: pwm@58e00 {
				compatible = "amlogic,meson-pwm-tee";
				reg = <0x0 0x58e00 0x0 0x24>;
				#pwm-cells = <3>;
				clocks = <&clkc CLKID_PWM_Q>;
				clock-names = "clkin0";
				tee_id = <16>;
				status = "disabled";
			};

			pwm_r: pwm@58f00 {
				compatible = "amlogic,meson-pwm-tee";
				reg = <0x0 0x58f00 0x0 0x24>;
				#pwm-cells = <3>;
				clocks = <&clkc CLKID_PWM_R>;
				clock-names = "clkin0";
				tee_id = <17>;
				status = "disabled";
			};

			pwm_s: pwm@59000 {
				compatible = "amlogic,meson-pwm-tee";
				reg = <0x0 0x59000 0x0 0x24>;
				#pwm-cells = <3>;
				clocks = <&clkc CLKID_PWM_S>;
				clock-names = "clkin0";
				tee_id = <18>;
				status = "disabled";
			};

			pwm_t: pwm@59100 {
				compatible = "amlogic,meson-pwm-tee";
				reg = <0x0 0x59100 0x0 0x24>;
				#pwm-cells = <3>;
				clocks = <&clkc CLKID_PWM_T>;
				clock-names = "clkin0";
				tee_id = <19>;
				status = "disabled";
			};

			i2c2: i2c@3a4000 {
				compatible = "amlogic,meson-i2c-v2-1";
				reg = <0x0 0x3a4000 0x0 0x3c>;
				interrupts = <GIC_SPI 162 IRQ_TYPE_EDGE_RISING>;
				#address-cells = <1>;
				#size-cells = <0>;
				clocks = <&clkc CLKID_SYS_I2C_M_C>;
				status = "disabled";
			};

			i2c3: i2c@3a4100 {
				compatible = "amlogic,meson-i2c-v2-1";
				reg = <0x0 0x3a4100 0x0 0x3c>;
				interrupts = <GIC_SPI 163 IRQ_TYPE_EDGE_RISING>;
				#address-cells = <1>;
				#size-cells = <0>;
				clocks = <&clkc CLKID_SYS_I2C_M_D>;
				status = "disabled";
			};

			i2c4: i2c@3a4200 {
				compatible = "amlogic,meson-i2c-v2-1";
				reg = <0x0 0x3a4200 0x0 0x3c>;
				interrupts = <GIC_SPI 164 IRQ_TYPE_EDGE_RISING>;
				#address-cells = <1>;
				#size-cells = <0>;
				clocks = <&clkc CLKID_SYS_I2C_M_E>;
				status = "disabled";
			};

			i2c5: i2c@3a4300 {
				compatible = "amlogic,meson-i2c-v2-1";
				reg = <0x0 0x3a4300 0x0 0x3c>;
				interrupts = <GIC_SPI 165 IRQ_TYPE_EDGE_RISING>;
				#address-cells = <1>;
				#size-cells = <0>;
				clocks = <&clkc CLKID_SYS_I2C_M_F>;
				status = "disabled";
			};

			i2c6: i2c@3a4400 {
				compatible = "amlogic,meson-i2c-v2-1";
				reg = <0x0 0x3a4400 0x0 0x3c>;
				interrupts = <GIC_SPI 166 IRQ_TYPE_EDGE_RISING>;
				#address-cells = <1>;
				#size-cells = <0>;
				clocks = <&clkc CLKID_SYS_I2C_M_G>;
				status = "disabled";
			};

			reset: reset-controller@2000 {
				compatible = "amlogic,meson-t7-reset";
				reg = <0x0 0x2000 0x0 0x98>;
				#reset-cells = <1>;
			};

			cpu_version {
				compatible = "amlogic,meson-gx-ao-secure", "syscon";
				reg=<0x0 0x10220 0x0 0x4>;
			};
		};

		aobus: bus@ffa00000 {
			compatible = "simple-bus";
			reg = <0x0 0xffa00000 0x0 0x100000>;
			#address-cells = <2>;
			#size-cells = <2>;
			ranges = <0x0 0x0 0x0 0xffa00000 0x0 0x100000>;

			ao_clkc: clock-controller@1 {
				compatible = "amlogic,c5-aoclkc";
				reg = <0x0 0x0 0x0 0x5c>;
				reg-names = "basic";
				#clock-cells = <1>;
				clocks = <&xtal>,
					<&xtal_32k>,
					<&osc_32m>,
					<&scmi_clk CLKID_SYS_CLK>,
					<&clkc CLKID_FCLK_DIV5>,
					<&clkc CLKID_FCLK_DIV4>,
					<&clkc CLKID_FCLK_DIV3>;
				clock-names = "xtal",
					      "xtal_32k",
					      "osc_32m",
					      "sys_clk",
					      "fclk_div5",
					      "fclk_div4",
					      "fclk_div3";
				status = "okay";
			};

			ao_pwm_a: pwm@10000 {
				compatible = "amlogic,meson-pwm-tee";
				reg = <0x0  0x10000 0x0 0x24>;
				#pwm-cells = <3>;
				clocks = <&clkc CLKID_AO_PWM_A>;
				clock-names = "clkin0";
				tee_id = <0>;
				status = "disabled";
			};

			ao_pwm_b: pwm@10200 {
				compatible = "amlogic,meson-pwm-tee";
				reg = <0x0 0x10200 0x0 0x24>;
				#pwm-cells = <3>;
				clocks = <&clkc CLKID_AO_PWM_B>;
				clock-names = "clkin0";
				tee_id = <1>;
				status = "disabled";
			};

			uart_AO_B: serial@1e000 {
				compatible = "amlogic,meson-uart";
				reg = <0x0 0x1e000 0x0 0x18>;
				interrupts = <GIC_SPI 64 IRQ_TYPE_EDGE_RISING>;
				status = "okay";
				clocks = <&xtal>;
				clock-names = "clk_uart";
				xtal_tick_en = <2>;
				fifosize = < 64 >;
				/* 0 not support; 1 support */
				support-sysrq = <1>;
			};

			uart_AO_A: serial@1a000 {
				compatible = "amlogic,meson-uart";
				reg = <0x0 0x1a000 0x0 0x18>;
				interrupts = <GIC_SPI 415 IRQ_TYPE_EDGE_RISING>;
				status = "disabled";
				clocks = <&xtal
					&clkc CLKID_AO_SYS_UART_A>;
				clock-names = "clk_uart", "clk_gate";
				fifosize = < 64 >;
				pinctrl-names = "default";
				pinctrl-0 = <&ao_a_uart_pins>;
			};

			ao_pinctrl: ao_pinctrl@4000 {
				compatible = "amlogic,meson-c5-ao-pinctrl";
				#address-cells = <2>;
				#size-cells = <2>;
				ranges;
				amlogic,ao-interrupt-controller;

				gpio_ao: ao-bank@4000 {
					reg = <0x0 0x4000 0x0 0x0020>,
					      <0x0 0x4080 0x0 0x0120>;
					reg-names = "mux", "gpio";
					gpio-controller;
					#gpio-cells = <2>;
					gpio-ranges = <&ao_pinctrl 0 0 48>;
				};
			};

			gpio_ao_intc: interrupt-controller@4040 {
				compatible = "amlogic,meson-c5-gpio-ao-intc",
					     "amlogic,meson-gpio-ao-intc";
				reg = <0x0 0x4040 0x0 0x30>;
				interrupt-controller;
				#interrupt-cells = <2>;
				amlogic,channel-interrupts =
					<384 385 386 387 388 389 390 391 392
					 393 394 395 396 397 398 399 400 401
					 402 403 >;
			};

			i2c0: i2c@e000 {
				compatible = "amlogic,meson-i2c-v2-1";
				reg = <0x0 0xe000 0x0 0x3c>;
				interrupts = <GIC_SPI 408 IRQ_TYPE_EDGE_RISING>;
				#address-cells = <1>;
				#size-cells = <0>;
				clocks = <&ao_clkc CLKID_AO_SYS_I2C_M_A>;
				status = "disabled";
			};

			i2c1: i2c@e100 {
				compatible = "amlogic,meson-i2c-v2-1";
				reg = <0x0 0xe100 0x0 0x3c>;
				interrupts = <GIC_SPI 409 IRQ_TYPE_EDGE_RISING>;
				#address-cells = <1>;
				#size-cells = <0>;
				clocks = <&ao_clkc CLKID_AO_SYS_I2C_M_B>;
				status = "disabled";
			};

			ao_reset: ao-reset-controller@2000 {
				compatible = "amlogic,meson-a9-ao-reset";
				reg = <0x0 0x2000 0x0 0xc>;
				#reset-cells = <1>;
			};
		};

		usbphy0: usbphy0@fe310000 {
			compatible = "amlogic,uphy-c5";
			#address-cells = <1>;
			#size-cells = <1>;
			status = "disabled";
			u2p0port0: u2p@0 {
				#phy-cells = <0>;
				port-speed = <0x0>; /* 0~2: HS HSP SS */
				reg = <0xfe310000 0x10
						0xfe002000 0x100
						0xfe010330 0x4
						0xfe314000 0x60>;
				reset-level = <0x40>;
				phy-reset-level-bits = <4>;
				usb-comb-reset-bit = <6>;
				phy-apb-reset-bit = <7>;
				pll-settings = <0x0
								0x0
								0x0
								0x7e18
								0x7>;
				interrupts = <0 139 IRQ_TYPE_EDGE_RISING>;
				clocks = <&clkc CLKID_SYS_USB_U3DRD>;
				clock-names = "sys_usb3";
				power-domains = <&pwrdm PDID_C5_USB3>;
			};

			u3p0port0: u3p@80 {
				#phy-cells = <0>;
				port-speed = <0x3>; /* 0~2: HS HSP SS */
				reg = <0xfe310080 0x20		/* phy3 cfg base */
						0xfe002000 0x100	/* reset base */
						0xfe312000 0x184	/* phy3 ctrl base */
						0xfe01034c 0x4>;	/* phy3 trim base */
				usb3-phy-reset-bit = /bits/ 8 <0x3>;
				usb3-apb-reset-bit = /bits/ 8 <0x2>;
				usb3-controller-reset-bit = /bits/ 8 <0x5>;
				reset-level-shift = <0x40>;
				clocks = <&clkc CLKID_SYS_USB_U3DRD>;
				clock-names = "sys_usb3";
				//pll-sw-cfg;
			};
		};

		usbphy1: usbphy1@fe300000 {
			compatible = "amlogic,uphy-c5";
			#address-cells = <1>;
			#size-cells = <1>;
			status = "disabled";
			u2p1port0: u2p@0 {
				#phy-cells = <0>;
				port-speed = <0x0>; /* 0~2: HS HSP SS */
				reg = <0xfe300000 0x10
						0xfe002000 0x100
						0xfe010330 0x4
						0xfe302000 0x60>;
				reset-level = <0x40>;
				phy-reset-level-bits = <0xb>;
				usb-comb-reset-bit = <0x9>;
				phy-apb-reset-bit = <0xa>;
				pll-settings = <0x0
								0x0
								0x0
								0x7e18
								0x7>;
				clocks = <&clkc CLKID_SYS_USB_U2H>;
				clock-names = "usb_general";
				power-domains = <&pwrdm PDID_C5_USB2>;
			};

		};

		dwc3otg1: dwc3otg1@0xfe310000{
			status = "disable";
			compatible = "amlogic,dwc3-meson-drd";
			reg = <0x0 0xfe310000 0x0 0x100>;
			phys = <&u2p0port0>;
			phy-names = "usb2-phy";
			interrupts = <GIC_SPI 139 IRQ_TYPE_EDGE_RISING>;
			ports {
				#address-cells = <1>;
				#size-cells = <0>;
				port@0 {
					reg = <0>;
					usb_otg1_ep: endpoint {
						remote-endpoint = <&usba_role_switch>;
					};
				};
			};
		};

		dwc3a: dwc3a@f3f00000 {
			status = "disable";
			compatible = "snps,dwc3-meson";
			maximum-speed = "super-speed";
			dr_mode = "host"; /*using role control mode, this must be otg*/
			//dr_mode = "peripheral";
			phy_type = "utmi";
			reg = <0x0 0xf3f00000 0x0 0x10000>;
			interrupts = <GIC_SPI 140 IRQ_TYPE_LEVEL_HIGH>;
			interrupt-names = "dwc_usb3";
			clocks = <&clkc CLKID_SYS_USB_U3DRD>, <&xtal>, <&xtal>;
			clock-names = "bus_early", "ref", "suspend";
			phys = <&u2p0port0>, <&u3p0port0>;
			phy-names = "usb2-phy", "usb3-phy";
			power-domains = <&pwrdm PDID_C5_USB3>;
			//resets = <&reset RESET_U3DRD>;
			snps,usb2-lpm-disable;
			//snps,usb3_lpm_capable;
			snps,usb2-gadget-lpm-disable;
			snps,has-lpm-erratum;
			/* better try */
			//snps,rx_detect_poll_quirk;
			snps,dis_u3_susphy_quirk;
			snps,dis_u2_susphy_quirk;
			snps,dis_enblslpm_quirk;
			/* why we do this? dwc3_ref_clk_period() */
			/* must enable GFLADJ_REFCLK_LPM_SEL */
			//snps,dis-u2-freeclk-exists-quirk;
			//snps,gfladj-refclk-lpm-sel-quirk;
			/* need post-silicon test. */
			//snps,quirk-frame-length-adjustment;
			snps,rx-thr-num-pkt = <2>;
			snps,rx-max-burst = <16>;
			snps,tx-thr-num-pkt = <2>;
			snps,tx-max-burst = <16>;
			tx-fifo-resize;
			tx-fifo-max-num = <3>;
			snps,incr-burst-type-adjustment = <4>;
			usb-role-switch;

			ports {
				#address-cells = <1>;
				#size-cells = <0>;
				port@0 {
					reg = <0>;
					usba_role_switch: endpoint {
						remote-endpoint = <&usb_otg1_ep>;
					};
				};
			};
		};

		dwc3otg2: dwc3otg2@0xfe300000{
			status = "disable";
			compatible = "amlogic,dwc3-meson-drd";
			reg = <0x0 0xfe300000 0x0 0x100>;
			phys = <&u2p1port0>;
			phy-names = "usb2-phy";
			interrupts = <GIC_SPI 139 IRQ_TYPE_EDGE_RISING>;
			ports {
				#address-cells = <1>;
				#size-cells = <0>;
				port@0 {
					reg = <0>;
					usb_otg2_ep: endpoint {
						remote-endpoint = <&usbb_role_switch>;
					};
				};
			};
		};

		dwc3b: dwc3b@f3c80000 {
			status = "disable";
			compatible = "snps,dwc3-meson";
			maximum-speed = "super-speed";
			dr_mode = "otg"; /*using role control mode, this must be otg*/
			//dr_mode = "peripheral";
			phy_type = "utmi";
			reg = <0x0 0xf3c80000 0x0 0x10000>;
			interrupts = <GIC_SPI 136 IRQ_TYPE_LEVEL_HIGH>;
			interrupt-names = "dwc_usb3";
			clocks = <&clkc CLKID_SYS_USB_U2H>, <&xtal>, <&xtal>;
			clock-names = "bus_early", "ref", "suspend";
			phys = <&u2p1port0>;
			phy-names = "usb2-phy";
			power-domains = <&pwrdm PDID_C5_USB2>;
			//resets = <&reset RESET_U3DRD>;
			snps,usb2-lpm-disable;
			//snps,usb3_lpm_capable;
			snps,usb2-gadget-lpm-disable;
			snps,has-lpm-erratum;
			/* better try */
			//snps,rx_detect_poll_quirk;
			snps,dis_u3_susphy_quirk;
			snps,dis_u2_susphy_quirk;
			snps,dis_enblslpm_quirk;
			/* why we do this? dwc3_ref_clk_period() */
			/* must enable GFLADJ_REFCLK_LPM_SEL */
			//snps,dis-u2-freeclk-exists-quirk;
			//snps,gfladj-refclk-lpm-sel-quirk;
			/* need post-silicon test. */
			//snps,quirk-frame-length-adjustment;
			snps,rx-thr-num-pkt = <2>;
			snps,rx-max-burst = <16>;
			snps,tx-thr-num-pkt = <2>;
			snps,tx-max-burst = <16>;
			tx-fifo-resize;
			tx-fifo-max-num = <3>;
			snps,incr-burst-type-adjustment = <4>;
			usb-role-switch;

			ports {
				#address-cells = <1>;
				#size-cells = <0>;
				port@0 {
					reg = <0>;
					usbb_role_switch: endpoint {
						remote-endpoint = <&usb_otg2_ep>;
					};
				};
			};
		};

		dolby_fw: dolby_fw {
			compatible = "amlogic, dolby_fw";
			mem_size = <0x100000>;
			status = "disabled";
		};

		pcie: pcie@f7b00000 {
			compatible = "amlogic, amlogic-pcie-v3";
			reg = <0x0 0xf7b00000 0x0 0x100000
				0x0 0xfe02c000 0x0 0x2000
				0x0 0xf4000000 0x0 0x4000000
				0x0 0xf7e00000 0x0 0x200000
				0x0 0xfe02a000 0x0 0x220
				0x0 0xfe002040 0x0 0x10
				0x0 0xfe01034c 0x0 0x4>;
			reg-names = "apb-base", "pcictrl-base", "axi-base",
				    "ecam-base", "aml-phy-base", "reset-base",
				    "pci-efuse";
			interrupts = <GIC_SPI 316 IRQ_TYPE_EDGE_RISING
				      GIC_SPI 312 IRQ_TYPE_EDGE_RISING
				      GIC_SPI 313 IRQ_TYPE_EDGE_RISING
				      GIC_SPI 314 IRQ_TYPE_EDGE_RISING
				      GIC_SPI 315 IRQ_TYPE_EDGE_RISING>;
			#interrupt-cells = <1>;
			msi-controller;
			msi-parent = <&pcie>;
			interrupt-parent = <&gic>;
			linux,pci-domain = <0>;
			bus-range = <0x0 0xff>;
			#address-cells = <3>;
			#size-cells = <2>;
			interrupt-map-mask = <0 0 0 7>;
			interrupt-map = <0 0 0 1 &gic GIC_SPI 312
					IRQ_TYPE_EDGE_RISING>,
					<0 0 0 2 &gic GIC_SPI 313
					IRQ_TYPE_EDGE_RISING>,
					<0 0 0 3 &gic GIC_SPI 314
					IRQ_TYPE_EDGE_RISING>,
					<0 0 0 4 &gic GIC_SPI 315
					IRQ_TYPE_EDGE_RISING>;
			device_type = "pci";
			ranges =
				/*
				 * downstream I/O
				 *
				 *  <0x81000000 0 0xf7800000 0 0xf7800000 0x0 0x200000
				 */
				/* non-prefetchable memory */
				<0x82000000 0 0xf4000000 0x0 0xf4000000 0 0x3800000>;
			num-lanes = <1>;
			pcie-num = <1>;
			phy-type = <2>;
			/*
			 * pinctrl-names = "default";
			 * pinctrl-0 = <&pcieck_pins>;
			 */

			//clocks = <&clkc CLKID_SYS_PCIEMAC>,
			//	 <&clkc CLKID_SYS_PCIE>,
			//	 <&clkc CLKID_PCIE_TL>;
			//clock-names = "pcie",
			//		"pcie_phy",
			//		"pcie_tl_clk";
			/* amlogic pcie phy pll */
			aml_phy_pll_version = <1>;
			pll_setting_number = <12>;
			/* <reg_offset vlaue> */
			phy_pll_setting_1 = <0x0000 0x03e855e9>;
			phy_pll_setting_2 = <0x0004 0x0009e085>;
			phy_pll_setting_3 = <0x0008 0x40000079>; /* bias_en=1 */
			phy_pll_setting_4 = <0x000c 0x3843a320>;
			phy_pll_setting_5 = <0x0010 0x50>;
			phy_pll_setting_6 = <0x0014 0x0009978b>;
			phy_pll_setting_7 = <0x0018 0x0>; /* select pll0 for debug */
			phy_pll_setting_8 = <0x0000 0x03e855ed>;
			phy_pll_setting_9 = <0x0004 0x0809e085>;
			phy_pll_setting_10 = <0x0000 0x0be855ed>;
			phy_pll_setting_11 = <0x0014 0x000b978b>;
			/* open ssc 5000 ppm
			 * phy_pll_setting_12 = <0x0008 0x4800007d>;
			 * phy_pll_setting_13 = <0x0010 0x2150e050>;
			 */
			phy_pll_setting_12 = <0x017c 0x3000000 >;

			/*reset-gpio-type
			 *0:Shared pad(no reset)
			 *1:OD pad2:Normal pad
			 */
			gpio-type = <2>;
			pcie-amlphy-rst-bit = <13>;
			pcie-apb-rst-bit = <14>;
			pcie-a-rst-bit = <12>;
			pcie-pipe-rst-bit = <11>;
			u3p2-phy-apb = <10>;
			pcie-rst-bit = <24>;
			pcie-rst-mask = <0xff>;
			//power-domains = <&pwrdm PDID_S6_PCIE>;
			status = "disabled";
			dma-ranges = <0x0 0x0 0x0 0x0 0x0 0x0 0xe0000000>;
		};

		sd_emmc_c: mmc@fe08c000 {
			compatible = "amlogic,meson-v8-mmc";
			reg = <0x0 0xfe08c000 0x0 0x1000>,
			      <0x0 0xfe000294 0x0 0x4>,
			      <0x0 0xfe004000 0x0 0x4>;
			interrupts = <GIC_SPI 178 IRQ_TYPE_EDGE_RISING>;
			status = "disabled";
			clocks = <&clkc CLKID_SYS_SD_EMMC_C>,
				 <&clkc CLKID_SD_EMMC_C_MUX>,
				 <&clkc CLKID_SD_EMMC_C>,
				 <&xtal>,
				 <&clkc CLKID_GP0_PLL>,
				 <&clkc CLKID_GP0_PLL>;
			clock-names = "core", "mux0", "mux1", "clkin0", "clkin1", "clkin2";
			card_type = <1>;
			ignore_desc_busy;
			mmc_debug_flag;
			src_clk_rate = <1152000000>;
			tx_delay = <0x10>;
			no-sd;
			no-sdio;
			//resets = <&reset RESET_SD_EMMC_C>;
		};

		sd_emmc_b: sd@fe08a000 {
			compatible = "amlogic,meson-v8-mmc";
			reg = <0x0 0xfe08a000 0x0 0x1000>,
			      <0x0 0xfe000290 0x0 0x4>,
			      <0x0 0xfe004024 0x0 0x4>;
			interrupts = <GIC_SPI 177 IRQ_TYPE_EDGE_RISING>;
			status = "disabled";
			clocks = <&clkc CLKID_SYS_SD_EMMC_B>,
				 <&clkc CLKID_SD_EMMC_B_MUX>,
				 <&clkc CLKID_SD_EMMC_B>,
				 <&xtal>,
				 <&clkc CLKID_FCLK_DIV2>;
			clock-names = "core", "mux0", "mux1", "clkin0", "clkin1";
			card_type = <5>;
			mmc_debug_flag;
			no-mmc;
			no-sdio;
			//resets = <&reset RESET_SD_EMMC_B>;
		};

		sd_emmc_a: sdio@fe088000 {
			compatible = "amlogic,meson-v8-mmc";
			reg = <0x0 0xfe088000 0x0 0x1000>,
			      <0x0 0xfe000290 0x0 0x4>,
			      <0x0 0xfe00400c 0x0 0x4>;
			interrupts = <GIC_SPI 176 IRQ_TYPE_LEVEL_HIGH>;
			status = "disabled";
			clocks = <&clkc CLKID_SYS_SD_EMMC_A>,
				 <&clkc CLKID_SD_EMMC_A_MUX>,
				 <&clkc CLKID_SD_EMMC_A>,
				 <&xtal>,
				 <&clkc CLKID_FCLK_DIV2>,
				 <&clkc CLKID_FCLK_DIV2>;
			clock-names = "core", "mux0", "mux1", "clkin0", "clkin1", "clkin2";
			card_type = <3>;
			mmc_debug_flag;
			cap-sdio-irq;
			keep-power-in-suspend;
			use_intf3_tuning;
			no-mmc;
			no-sd;
			//resets = <&reset RESET_SD_EMMC_A>;
		};

		mtd_nand: nfc@fe08c800 {
			compatible = "amlogic,meson-nfc-single-ecc-bl2ex";
			status = "disabled";
			reg = <0x0 0xfe08c800 0x0 0x200>;
			interrupts = <GIC_SPI 175 IRQ_TYPE_EDGE_RISING>;

			//clocks = <&clkc CLKID_NAND>,
			//		 <&clkc CLKID_FCLK_DIV2>;
			//clock-names = "gate", "fdiv2pll";
			nand_clk_ctrl = <0xfe08c000>;
		};

		ethmac: ethernet@fe368000 {
			compatible = "amlogic,meson-axg-dwmac",
				     "snps,dwmac-4.00";
			reg = <0x0 0xfe368000 0x0 0x12ec>,
			      <0x0 0xfe364000 0x0 0x8>;
			interrupts = <GIC_SPI 190 IRQ_TYPE_LEVEL_HIGH>;
			interrupt-names = "macirq";
			clocks = <&clkc CLKID_SYS_ETH_MAC>,
				 <&clkc CLKID_FCLK_DIV2>,
				 <&clkc CLKID_FCLK_DIV50M>;
			clock-names = "stmmaceth", "clkin0", "clkin1";
			rx-fifo-depth = <4096>;
			tx-fifo-depth = <2048>;
			mboxes = <&mbox_fifo C5_REE2AO_ETH>;
			status = "disabled";
			ext_mdio: mdio {
				#address-cells = <1>;
				#size-cells = <0>;
				compatible = "snps,dwmac-mdio";
				external_phy: ethernet-phy@0 {
					reg = <0>;
					max-speed = <1000>;
					reset-assert-us = <20000>;
					reset-deassert-us = <50000>;
					reset-gpios = <&gpio GPIOF_3 (GPIO_ACTIVE_LOW |
								GPIO_OPEN_DRAIN)>;
				};
			};
		};

		uart_B: serial@fe07a000 {
			compatible = "amlogic,meson-uart";
			reg = <0x0 0xfe07a000 0x0 0x18>;
			interrupts = <GIC_SPI 169 IRQ_TYPE_EDGE_RISING>;
			status = "disabled";
			clocks = <&xtal
				&clkc CLKID_SYS_UART_B>;
			clock-names = "clk_uart", "clk_gate";
			xtal_tick_en = <2>;
			fifosize = < 64 >;
			pinctrl-names = "default";
			/* can't use ao_b pinmux */
			pinctrl-0 = <&b_uart_pins>;
		};

		uart_C: serial@fe07c000 {
			compatible = "amlogic,meson-uart";
			reg = <0x0 0xfe07c000 0x0 0x18>;
			interrupts = <GIC_SPI 170 IRQ_TYPE_EDGE_RISING>;
			status = "disabled";
			clocks = <&xtal
				&clkc CLKID_SYS_UART_C>;
			clock-names = "clk_uart", "clk_gate";
			fifosize = < 64 >;
			pinctrl-names = "default";
			pinctrl-0 = <&c_uart_pins>;
		};

		uart_D: serial@fe07e000 {
			compatible = "amlogic,meson-uart";
			reg = <0x0 0xfe07e000 0x0 0x18>;
			interrupts = <GIC_SPI 171 IRQ_TYPE_EDGE_RISING>;
			status = "disabled";
			clocks = <&xtal
				&clkc CLKID_SYS_UART_D>;
			clock-names = "clk_uart", "clk_gate";
			fifosize = < 64 >;
			pinctrl-names = "default";
			pinctrl-0 = <&d_uart_pins>;
		};

		uart_E: serial@fe080000 {
			compatible = "amlogic,meson-uart";
			reg = <0x0 0xfe080000 0x0 0x18>;
			interrupts = <GIC_SPI 172 IRQ_TYPE_EDGE_RISING>;
			status = "disabled";
			clocks = <&xtal
				&clkc CLKID_SYS_UART_E>;
			clock-names = "clk_uart", "clk_gate";
			fifosize = < 64 >;
			pinctrl-names = "default";
			pinctrl-0 = <&e_uart_pins1>;
		};

		uart_F: serial@fe082000 {
			compatible = "amlogic,meson-uart";
			reg = <0x0 0xfe082000 0x0 0x18>;
			interrupts = <GIC_SPI 167 IRQ_TYPE_EDGE_RISING>;
			status = "disabled";
			clocks = <&xtal
				&clkc CLKID_SYS_UART_F>;
			clock-names = "clk_uart", "clk_gate";
			fifosize = < 64 >;
			pinctrl-names = "default";
			pinctrl-0 = <&f_uart_pins>;
		};
	};

	mesonstream {
		compatible = "amlogic, codec, streambuf";
		dev_name = "mesonstream";
		status = "okay";
	};

	vcodec_dos_dev: vcodec_dos_dev {
		compatible = "amlogic, cpu-major-id-c5";
		dev_name = "vcodec_dos_dev";
		status = "okay";
		reg = <0x0 0xfe320000 0x0 0x10000>,
			<0x0 0xfe036000 0x0 0x2000>,
			<0x0 0xfe010000 0x0 0x2000>;
		reg-names = "dosbus",
			"dmcbus",
			"sysctrl";
		clocks = <&clkc CLKID_SYS_DOS
			&clkc CLKID_HEVCF>;
		clock-names = "vdec",
			"clk_hevcf_mux";
		assigned-clock-parents = <&clkc CLKID_HEVCF_0>;
		assigned-clocks = <&clkc CLKID_HEVCF>;
	};

	vdec {
		compatible = "amlogic, vdec-pm-pd";
		dev_name = "vdec.0";
		status = "okay";
		interrupts = <0 3 1
			0 155 1
			0 32 1
			0 87 1
			0 88 1
			0 89 1
			0 252 1
			0 201 1
			0 113 1>;
		interrupt-names = "vsync",
			"demux",
			"parser",
			"mailbox_0",
			"mailbox_1",
			"mailbox_2",
			"assist_mbox_irq_ee",
			"viff_empty",
			"axi_monitor";
		power-domains = <&pwrdm PDID_C5_DOS_HEVC>,
			<&pwrdm PDID_C5_DOS_HCODEC>;
		power-domain-names = "pwrc-hevc",
			"pwrc-hcodec";
		reset-names = "hevcf_dmc_pipel";
		resets = <&reset RESET_BRG_HEVCF_DMC_PIPEL>;
	};

	vcodec_dec {
		compatible = "amlogic, vcodec-dec";
		dev_name = "aml-vcodec-dec";
		status = "okay";
	};

	ddr_bandwidth {
		compatible = "amlogic,ddr-bandwidth-c5";
		status = "okay";
		reg = <0x0 0xfe036000 0x0 0x1000
		       0x0 0xfe036ca8 0x0 0x4>;
		interrupts = <0 78 IRQ_TYPE_EDGE_RISING>;
		interrupt-names = "ddr_bandwidth";
	};

	dmc_monitor {
		compatible = "amlogic,dmc_monitor-c5";
		status = "okay";
		memory-region = <&dmc_reserved>;
		reg = <0x0 0xfe036000 0x0 0x400>;
		reg_base = <0xfe036000>;
		interrupts = <0 62 IRQ_TYPE_LEVEL_HIGH
			      0 61 IRQ_TYPE_EDGE_RISING>;
	};

	amhdmitx: amhdmitx{
		compatible = "amlogic, amhdmitx-s6";
		dev_name = "amhdmitx";
		status = "disabled";
		//power-domains = <&pwrdm PDID_T7_VI_CLK2>;
		vend-data = <&vend_data>;
		pinctrl-names="hdmitx_hpd", "hdmitx_ddc";
		pinctrl-0=<&hdmitx_hpd>;
		pinctrl-1=<&hdmitx_ddc>;
		//hdmitx-gpios-hpd = <&gpio GPIOH_2 GPIO_ACTIVE_HIGH>;
		//hdmitx-gpios-scl = <&gpio GPIOH_1 GPIO_ACTIVE_HIGH>;
		//hdmitx-gpios-sda = <&gpio GPIOH_0 GPIO_ACTIVE_HIGH>;
		interrupts = <GIC_SPI 204 IRQ_TYPE_LEVEL_HIGH
			GIC_SPI 197 IRQ_TYPE_EDGE_RISING>;
		interrupt-names = "hdmitx_hpd", "vrr_vsync";
		enc_idx = <0>;
		max_refresh_rate = <120>; /* the max fresh_rate of S6 is upto 120hz */
		reg =	<0x0 0xff000000 0x0 0x40000>,
			<0x0 0xfe310000 0x0 0x10000>,
			<0x0 0xfe300000 0x0 0x10000>,
			<0x0 0xfe010000 0x0 0x2000>,
			<0x0 0xfe00c000 0x0 0x2000>,
			<0x0 0xfe008000 0x0 0x2000>,
			<0x0 0xfe002000 0x0 0x2000>,
			<0x0 0xfe000000 0x0 0x2000>,
			<0x0 0xfe004000 0x0 0x200>;
		reg-names = "vpu",
			    "hdmitxcor",
			    "hdmitxtop",
			    "sysctrl",
			    "pwrctrl",
			    "anactrl",
			    "resetctrl",
			    "clkctrl",
			    "padctrl";
		frac_enable = <1>;

		vend_data: vend_data{ /* Should modified by Customer */
			vendor_name = "CUS_NAME"; /* Max Chars: 8 */
			product_desc = "PRODUCT_NAME"; /* Max Chars: 16 */
			/* standards.ieee.org/develop/regauth/oui/oui.txt */
			vendor_id = <0x000000>;
		};

		ports {
			port {
				#address-cells = <1>;
				#size-cells = <0>;
				hdmitx_to_drm: endpoint@0 {
					reg = <0>;
					remote-endpoint = <0>;
				};
			};
		};
	};

	aocec: aocec {
		compatible = "amlogic, aocec-s6";
		dev_name = "aocec";
		status = "disabled";
		vendor_name = "Amlogic"; /* Max Chars: 8     */
		/* Refer to the following URL at:
		 * http://standards.ieee.org/develop/regauth/oui/oui.txt
		 */
		vendor_id = <0xffffff>;
		product_desc = "S6"; /* Max Chars: 16    */
		cec_osd_string = "AML_MBOX"; /* Max Chars: 14    */
		cec_version = <5>;/*5:1.4;6:2.0*/
		port_num = <1>;
		output = <1>;
		cec_sel = <1>;/*1:use one ip, 2:use 2 ip*/
		ee_cec;
		arc_port_mask = <0x1>;
		interrupts = <GIC_SPI 180 IRQ_TYPE_EDGE_RISING>;/*1:ts*/
		interrupt-names = "hdmi_aocecb";
		pinctrl-names = "default","hdmitx_aocecb","cec_pin_sleep";
		pinctrl-0=<&eecec_b>;
		pinctrl-1=<&eecec_b>;
		pinctrl-2=<&eecec_b>;
		//clocks = <&clkc CLKID_CECB_DUAL>;
		//clock-names = "cecb_clk";
		reg = <0x0 0xfe044000 0x0 0x2ff
		       0x0 0xfe010000 0x0 0xfff
		       0x0 0xfe000000 0x0 0xfff
		       0x0 0xfe004000 0x0 0x2000>;
		reg-names = "ao","periphs","clock","pad_reg";
		mbox-names = "mbox_cec";
		mboxes = <&mbox_fifo C5_REE2AO_AOCEC>;
	};

	aml_dma {
		compatible = "amlogic,aml_p1_dma";
		reg = <0x0 0xfe440400 0x0 0x48>;
		interrupts = <0 24 1>;
		dma_bus64 = /bits/ 8 <0x1>;

		aml_aes {
			compatible = "amlogic,aes_g12a_dma";
			dev_name = "aml_aes_dma";
			status = "okay";
			iv_swap = /bits/ 8 <0x0>;
		};

		aml_sha {
			compatible = "amlogic,sha_dma";
			dev_name = "aml_sha_dma";
			hw_ctx_sz = /bits/ 32 <0x28>;
			status = "okay";
		};

		aml_sha3 {
			compatible = "amlogic,sha3_dma";
			dev_name = "aml_sha3_dma";
			status = "disabled";
		};

		aml_tdes {
			compatible = "amlogic,des_dma,tdes_dma";
			dev_name = "aml_tdes_dma";
			status = "okay";
		};

		aml_sm4 {
			compatible = "amlogic,sm4_dma";
			dev_name = "aml_sm4_dma";
			status = "disabled";
			iv_swap = /bits/ 8 <0x0>;
		};

		crypto {
			compatible = "amlogic,crypto_s5";
			dev_name = "aml_crypto_dev";
			status = "okay";
			thread = /bits/ 8 <0x1>;
			interrupts = <0 25 1>;
		};
	};

	rng {
		compatible = "amlogic,meson-rng";
		status = "okay";
		#address-cells = <2>;
		#size-cells = <2>;
		reg = <0x0 0xfe440788 0x0 0x0c>;
		quality = /bits/ 16 <1000>;
		version = <2>;
	};

	canvas: canvas{
		compatible = "amlogic, meson, canvas";
		status = "okay";
	};

	codec_io: codec_io {
		compatible = "amlogic, meson-c5, codec-io";
		status = "okay";
		#address-cells=<2>;
		#size-cells=<2>;
		ranges;
		reg =	<0x0 0x0 0x0 0x0>,
			<0x0 0x0 0x0 0x0>,
			<0x0 0xfe000000 0x0 0x800>,
			<0x0 0x0 0x0 0x00>,
			<0x0 0xff500000 0x0 0x40000>,
			<0x0 0xfe036000 0x0 0x2000>,
			<0x0 0x0 0x0 0x0>;
		reg-names = "cbus",
			    "dosbus",
			    "hiubus",
			    "aobus",
			    "vcbus",
			    "dmcbus",
			    "efusebus";
	};
	jpegenc {
		compatible = "amlogic, jpegenc";
		dev_name = "jpegenc";
		status = "okay";
		power-domains = <&pwrdm PDID_C5_DOS_HCODEC>;
		clocks = <&clkc CLKID_SYS_DOS
			&clkc CLKID_HCODEC>;
		clock-names = "clk_dos",
			"clk_jpeg_enc";
		interrupts = <0x00 0x57 0x01>;
		interrupt-names = "mailbox_0";
	};
	tahoe {
		compatible = "amlogic, tahoe";
		dev_name = "tahoe";
		status = "okay";
		reg = <0x0 0xfe370000 0x0 0x400000>;
		power-domains = <&pwrdm PDID_C5_TAHOE>;
		clocks = <&clkc CLKID_SYS_TAHOE
			&clkc CLKID_HCODEC>;
		clock-names = "clk_tahoe_dos",
			"clk_tahoe_enc";
		interrupts = <0x00 0x103 0x01>,
			<0x00 0x22 0x01>,
			<0x00 0x23 0x01>,
			<0x00 0x24 0x01>,
			<0x00 0x25 0x01>,
			<0x00 0x26 0x01>, //4
			<0x00 0x27 0x01>,
			<0x00 0x28 0x01>,
			<0x00 0x29 0x01>,
			<0x00 0x2a 0x01>,
			<0x00 0x2b 0x01>,
			<0x00 0xe4 0x01>,
			<0x00 0xe5 0x01>,
			<0x00 0xe6 0x01>,//12
			<0x00 0xe7 0x01>,
			<0x00 0xe8 0x01>,
			<0x00 0xe9 0x01>,
			<0x00 0xea 0x01>,
			<0x00 0xeb 0x01>,
			<0x00 0xec 0x01>,
			<0x00 0xed 0x01>,
			<0x00 0xee 0x01>;
		interrupt-names = "tahoe_irq0",
			"tahoe_sp_irq0",
			"tahoe_sp_irq1",
			"tahoe_sp_irq2",
			"tahoe_sp_irq3",
			"tahoe_sp_irq4",
			"tahoe_sp_irq5",
			"tahoe_sp_irq6",
			"tahoe_sp_irq7",
			"tahoe_sp_irq8",
			"tahoe_sp_irq9",
			"tahoe_sp_irq10",
			"tahoe_sp_irq11",
			"tahoe_sp_irq12",
			"tahoe_sp_irq13",
			"tahoe_sp_irq14",
			"tahoe_sp_irq15",
			"tahoe_sp_irq16",
			"tahoe_sp_irq17",
			"tahoe_sp_irq18",
			"tahoe_sp_irq19",
			"tahoe_sp_irq20";
	};

	vc9000e_rev {
		compatible = "vc9000e_rev";
		dev_name = "vc9000e";
		status = "disabled";
		//clocks = <&clkc CLKID_SYS_VC9000E>,
		//	<&clkc CLKID_VC9000E_CORE>,
		//	<&clkc CLKID_VC9000E_AXI>;
		//clock-names = "vers_sys_clk",
		//	"vers_core_clk",
		//	"vers_aclk";
		interrupts = <GIC_SPI 259 IRQ_TYPE_EDGE_RISING
			GIC_SPI 256 IRQ_TYPE_EDGE_RISING
			GIC_SPI 257 IRQ_TYPE_EDGE_RISING
			GIC_SPI 258 IRQ_TYPE_EDGE_RISING>;
		interrupt-names = "vc9000e_active_irq",
			"vc9000e_irq0",
			"vc9000e_irq1",
			"vc9000e_irq2";
		//power-domains = <&pwrdm PDID_S6_VC9000E>;
		reset-names = "vc9000e_areset", "vc9000e_core_rst", "vc9000e_apb_reset";
		//resets = <&reset RESET_VC9000E>,
		//	<&reset RESET_VC9000E_CORE>,
		//	<&reset RESET_VC9000E_APB>;
		#address-cells=<2>;
		#size-cells=<2>;
		ranges;
		/* use cbus space for reset_ctrl*/
		reg = <0x0 0xfe370000 0x0 0x10000>,
			<0x0 0xfe096000 0x0 0x2000>;
		reg-names = "vc9000e_core",
			"vc9000e_top";
	};
	vpu: vpu {
		compatible = "amlogic, vpu-c5";
		status = "okay";
		reg =	<0x0 0xfe000000 0x0 0x2000    /* clk */
			 0x0 0xfe00c000 0x0 0x70     /* pwrctrl */
			 0x0 0xff500000 0x0 0x10000>; /* vcbus */
		clocks = <&clkc CLKID_VAPB>,
			<&clkc CLKID_VOUT_MCLK>;
		clock-names =	"vapb_clk",
				"vpu_clk";
		clk_level = <5>;
		/* 0: 24.0M  1: 100.0M    2: 166.7M    3: 200.0M    4: 250.0M */
		/* 5: 333.3M */
	};

	rdma {
		compatible = "amlogic, meson-t7, rdma";
		status = "disabled";
		interrupts = <GIC_SPI 215 IRQ_TYPE_EDGE_RISING>;
		interrupt-names = "rdma";
		/* after sc2 */
		reset-names = "rdma";
		//resets = <&reset RESET_RDMA>;
	};

	amlvecm: amlvecm {
		compatible = "amlogic, vecm-c5";
		dev_name = "aml_vecm";
		status = "okay";
		gamma_en = <0>;/*1:enable ;0:disable*/
		wb_en = <0>;/*1:enable ;0:disable*/
		/*0: 709/601  1: bt2020*/
		tx_op_color_primary = <0>;
	};

	aml_primesl {
		compatible = "amlogic, prime_sl_s6";
		dev_name = "amprime_sl";
		status = "disabled";
	};

	multi-di {
		compatible = "amlogic, dim-s7d";
		/* s6 same as s7d */
		status = "disabled";
		/* 0:use reserved; 1:use cma; 2:use cma as reserved */
		flag_cma = <4>;	//<1>;
		//memory-region = <&di_reserved>;
		//memory-region = <&di_cma_reserved>;
		interrupts = <0 203 1
				0 202 1>;
		//interrupt-names = "pre_irq", "post_irq";
		//clocks = <&clkc CLKID_VPU_CLKB>,
		//	<&clkc CLKID_VPU>;
		//clock-names = "vpu_clkb",
		//	"vpu_mux";
		clock-range = <334 667>;
		/* buffer-size = <3621952>;(yuv422 8bit) */
		buffer-size = <4074560>;/*yuv422 fullpack*/
		/* reserve-iomap = "true"; */
		/* if enable nr10bit, set nr10bit-support to 1 */
		post-wr-support = <1>;
		nr10bit-support = <1>;
		nrds-enable = <1>;
	};

	vclk_serve: vclk_serve {
		compatible = "amlogic, vclk_serve";
		status = "okay";
		reg = <0x0 0xfe008000 0x0 0x800    /* ana reg */
			0x0 0xfe000000 0x0 0x800>; /* clk reg */
	};

	vout_sys: vout_sys {
		compatible = "amlogic, vout_sys_serve";
		status = "okay";
		reg = <0x0 0xfe01029c 0x0 0x4>;
	};

	vdac {
		compatible = "amlogic, vdac-s4d";
		status = "disabled";
	};

	vout: vout {
		compatible = "amlogic, vout";
		status = "okay";

		/* fr_policy:
		 *    0: disable
		 *    1: nearby (only for 60->59.94 and 30->29.97)
		 *    2: force (60/50/30/24/59.94/23.97)
		 */
		fr_policy = <2>;
	};

	vout2: vout2 {
		compatible = "amlogic, vout2";
		status = "disabled";

		/* fr_policy:
		 *    0: disable
		 *    1: nearby (only for 60->59.94 and 30->29.97)
		 *    2: force (60/50/30/24/59.94/23.97)
		 */
		fr_policy = <2>;
	};

	vout_mux: vout_mux {
		compatible = "amlogic, vout_mux";
		status = "okay";
		//clocks = <&clkc CLKID_FCLK_DIV5>, <&clkc CLKID_VDIN_MEAS>;
		//clock-names = "fclk_div5", "vdin_meas_clk";
	};

	dummy_venc: dummy_venc {
		compatible = "amlogic, dummy_venc_s4";
		status = "disabled";

		ports {
			port {
				#address-cells = <1>;
				#size-cells = <0>;
				dummyl_to_drm: endpoint@0 {
					reg = <0>;
					remote-endpoint = <0>;
				};
			};
		};
	};

	adc: adc {
		compatible = "amlogic, adc-s4d";
		status = "disabled";
		reg = <0x0 0xff654000 0x0 0x2000/* afe reg base */
			0x0 0xfe008000 0x0 0x2000/* hiu base */
			>;
	};

	ir: ir@8000 {
		compatible = "amlogic, meson-ir";
		reg = <0x0 0xffa2e080 0x0 0xA4>,
			<0x0 0xffa2e000 0x0 0x58>;
		status = "disable";
		protocol = <REMOTE_TYPE_NEC>;
		interrupts = <GIC_SPI 411 IRQ_TYPE_EDGE_RISING>;
		map = <&custom_maps>;
		wakeup_map = <&ir_wakeup_key>;
		mboxes = <&mbox_fifo C5_REE2AO_IR>;
		max_frame_time = <200>;
	};

	nna_tsensor: nna_tsensor@fe022000 {
		compatible = "amlogic, r1p1-tsensor";
		status = "okay";
		reg = <0x0 0xfe022000 0x0 0x50>;
		tsensor_id = <1>;
		cal_type = <0x11>;
		cal_coeff = <270 370 2747 9164>;
		rtemp = <110000>;
		interrupts = <GIC_SPI 22 IRQ_TYPE_LEVEL_HIGH>;
		clocks = <&clkc CLKID_TS>;
		clock-names = "ts_comp";
		reset-names = "ts_rst";
		resets = <&reset RESET_TS_NNA>;
		#thermal-sensor-cells = <1>;
	};

	isp_tsensor: isp_tsensor@fe02a000 {
		compatible = "amlogic, r1p1-tsensor";
		status = "okay";
		reg = <0x0 0xfe02a000 0x0 0x50>;
		tsensor_id = <2>;
		cal_type = <0x11>;
		cal_coeff = <270 370 2747 9164>;
		rtemp = <110000>;
		interrupts = <GIC_SPI 31 IRQ_TYPE_LEVEL_HIGH>;
		clocks = <&clkc CLKID_TS>;
		clock-names = "ts_comp";
		reset-names = "ts_rst";
		resets = <&reset RESET_TS_ISP>;
		#thermal-sensor-cells = <1>;
	};

	pll_tsensor: pll_tsensor@fe020000 {
		compatible = "amlogic, r1p1-tsensor";
		status = "okay";
		reg = <0x0 0xfe020000 0x0 0x50>;
		tsensor_id = <3>;
		cal_type = <0x11>;
		cal_coeff = <270 370 2747 9164>;
		rtemp = <110000>;
		interrupts = <GIC_SPI 30 IRQ_TYPE_LEVEL_HIGH>;
		clocks = <&clkc CLKID_TS>;
		clock-names = "ts_comp";
		reset-names = "ts_rst";
		resets = <&reset RESET_TS_PLL>;
		#thermal-sensor-cells = <1>;
	};

	thermal-zones {
		nna_thermal: nna_thermal {
			polling-delay = <1000>;
			polling-delay-passive = <100>;
			sustainable-power = <1160>;
			thermal-sensors = <&nna_tsensor 0>;
			trips {
				nna_switch_on: trip-point@0 {
					temperature = <85000>;
					hysteresis = <5000>;
					type = "passive";
				};
				nna_control: trip-point@1 {
					temperature = <95000>;
					hysteresis = <5000>;
					type = "passive";
				};
				nna_critical: trip-point@2 {
					temperature = <105000>;
					hysteresis = <1000>;
					type = "critical";
				};
			};
		};

		isp_thermal: isp_thermal {
			polling-delay = <1000>;
			polling-delay-passive = <100>;
			sustainable-power = <1160>;
			thermal-sensors = <&isp_tsensor 1>;
			trips {
				isp_switch_on: trip-point@0 {
					temperature = <85000>;
					hysteresis = <5000>;
					type = "passive";
				};
				isp_control: trip-point@1 {
					temperature = <95000>;
					hysteresis = <5000>;
					type = "passive";
				};
				isp_critical: trip-point@2 {
					temperature = <105000>;
					hysteresis = <1000>;
					type = "critical";
				};
			};
		};

		soc_thermal: soc_thermal {
			polling-delay = <1000>;
			polling-delay-passive = <100>;
			sustainable-power = <1160>;
			thermal-sensors = <&pll_tsensor 2>;
			trips {
				pll_switch_on: trip-point@0 {
					temperature = <85000>;
					hysteresis = <5000>;
					type = "passive";
				};
				pll_control: trip-point@1 {
					temperature = <95000>;
					hysteresis = <5000>;
					type = "passive";
				};
				pll_critical: trip-point@2 {
					temperature = <105000>;
					hysteresis = <1000>;
					type = "critical";
				};
			};

			cooling-maps {
				cooling_map {
					trip = <&pll_control>;
					cooling-device = <&CPU0 0 8>;
					contribution = <1024>;
				};
			};
		};
	};/*thermal zone end*/

	ddr_control: ddr_control {
		compatible = "amlogic, ddr-control";
		reg = <0 0xfe036c14 0 0x4>,
		      <0 0xfe036ca8 0 0x4>;
		reg-names = "type-addr",
			    "freq-addr";
		type-mask = <8 8>;
		freq-mask = <0 16>;
		status = "disabled";
		lpddr4 {
			particle = <LPDDR4_PARTICLE>;
			particle-flag = <DDR_TYPE_FLAG>;
			condition-type = <DDR_THERMAL>;
			freq-divisor = <1 4>;
			zone-name = "soc_thermal";
			caddr = <0xfe0364b4>,
				<0xfe0365b4>;
			caddr-mask = <0 16>,
				     <0 16>;
			cstep-val = <85000 90000 95000 100000>,
				    <105000 110000 115000 120000>;
			caddr-val = <3900 1950>,
				    <3120 1560>,
				    <2437 1219>,
				    <2437 1219>,
				    <1950 975>,
				    <1560 780>,
				    <1218 609>,
				    <975  488>;
		};

		lpddr4x {
			particle = <LPDDR4X_PARTICLE>;
			particle-flag = <DDR_TYPE_FLAG>;
			condition-type = <DDR_THERMAL>;
			freq-divisor = <1 4>;
			zone-name = "soc_thermal";
			caddr = <0xfe0364b4>,
				<0xfe0365b4>;
			caddr-mask = <0 16>,
				     <0 16>;
			cstep-val = <85000 90000 95000 100000>,
				    <105000 110000 115000 120000>;
			caddr-val = <3900 1950>,
				    <3120 1560>,
				    <2437 1219>,
				    <2437 1219>,
				    <1950 975>,
				    <1560 780>,
				    <1218 609>,
				    <975  488>;
		};

		lpddr5 {
			particle = <LPDDR5_PARTICLE>;
			particle-flag = <DDR_TYPE_FLAG>;
			condition-type = <DDR_THERMAL>;
			freq-divisor = <1 1>;
			zone-name = "soc_thermal";
			caddr = <0xfe0364b4>,
				<0xfe0365b4>;
			caddr-mask = <0 16>,
				     <0 16>;
			cstep-val = <85000 90000 95000 100000>,
				    <105000 110000 115000 120000>;
			caddr-val = <3900 1950>,
				    <3120 1560>,
				    <2437 1219>,
				    <2437 1219>,
				    <1950 975>,
				    <1560 780>,
				    <1218 609>,
				    <975  488>;
		};
	};

	ion_dev {
		compatible = "amlogic, ion_dev";
		//memory-region = <&ion_cma_reserved
		//		&ion_fb_reserved>;
	};

	gpu_protected_memory_allocator: protected-memory-allocator {
		compatible = "arm,protected-memory-allocator";
		//memory-region = <&mali_protected>;
	};

	meson_uvm {
		compatible = "amlogic, meson_uvm";
		status = "okay";
	};

	meson_videotunnel{
		compatible = "amlogic, meson_videotunnel";
		status = "disabled";
	};

	fb: fb {
		compatible = "amlogic, fb-s6";
		memory-region = <&logo_reserved>;
		status = "disabled";
		interrupts = <GIC_SPI 197 IRQ_TYPE_EDGE_RISING
			GIC_SPI 194 IRQ_TYPE_EDGE_RISING
			GIC_SPI 215 IRQ_TYPE_EDGE_RISING>;
		interrupt-names = "viu-vsync", "viu2-vsync", "rdma";
		/* uboot logo,fb0/fb1 memory size,if afbcd fb0=0x01851000*/
		display_mode_default = "1080p60hz";
		scale_mode = <1>;
		/** 0:VPU free scale 1:OSD free scale 2:OSD super scale */
		display_size_default = <1920 1080 1920 2160 32>;
		/*1920*1080*4*3 = 0x17BB000*/
		display_device_cnt = <2>;
		//clocks = <&clkc CLKID_VPU_CLKC>;
		//clock-names = "vpu_clkc";
	};

	irblaster: meson-irblaster@fe08414c {
		compatible = "amlogic, meson_irblaster";
		status = "disabled";
		reg = <0x0 0xfe08414c 0x0 0x10>;
		#irblaster-cells = <2>;
		interrupts = <GIC_SPI 81 IRQ_TYPE_EDGE_RISING>;
	};

	/*if you want to use vdin just modify status to "ok"*/
	vdin0: vdin0 {
		compatible = "amlogic, vdin-s6";
		dev_name = "vdin0";
		status = "disabled";
		reserve-iomap = "true";
		/*bit8: 0-total buffer num apply,1-one buffer apply*/
		flag_cma = <101>;/*1:share with codec_mm;2:cma alone*/
		/*MByte, if 10bit disable: 64M(YUV422),
		 *if 10bit enable: 64*1.5 = 96M(YUV422)
		 *if support 4K2K-YUV444-10bit-WR:3840*2160*4*4 ~= 128M
		 *if support 4K2K-YUV422-10bit-wr:3840*2160*3*4 ~= 96M
		 *if support 4K2K-YUV422-8BIT-WR:3840*2160*2*4 ~= 64M
		 *if support 1080p-YUV422-8BIT-WR:1920*1080*2*4 ~= 16M
		 */
		/*cma_size = <16>;*/
		interrupts = <0 210 1>;
		interrupt-names = "vsync_int";
		rdma-irq = <2>;
		//clocks = <&clkc CLKID_FCLK_DIV5>, <&clkc CLKID_VDIN_MEAS>;
		//clock-names = "fclk_div5", "cts_vdin_meas_clk";
		vdin_id = <0>;
		/* vdin v4l2 */
		v4l_support_en = <0>;
		v4l_vd_num = <70>;
		/* v4l2 capability */
		driver   = "vdin_video";
		card     = "meson-s6";
		bus_info = "vdin0 v4l2";
		version  = <0x20220120>;
		/* fe_ports refer to tvin.h */
		fe_ports = <0x00001001   /* CVBS1 */
			0x00010000   /* MIPI */
			0x00004000   /* HDMI0 */
			0x00004001   /* HDMI1 */
			0x00004002>; /* HDMI2 */
		/* vdin v4l2 end */
	};
	vdin1: vdin1 {
		compatible = "amlogic, vdin-s6";
		dev_name = "vdin1";
		status = "disabled";
		reserve-iomap = "true";
		flag_cma = <0>;/*1:share with codec_mm;0:cma alone*/
		interrupts = <0 212 1>;
		interrupt-names = "vsync_int";
		rdma-irq = <4>;
		//clocks = <&clkc CLKID_FCLK_DIV5>, <&clkc CLKID_VDIN_MEAS>;
		//clock-names = "fclk_div5", "cts_vdin_meas_clk";
		vdin_id = <1>;
		/* vdin v4l2 */
		v4l_support_en = <0>;
		v4l_vd_num = <71>;
		/* v4l2 capability */
		driver   = "vdin_video";
		card     = "meson-s6";
		bus_info = "vdin1 v4l2";
		version  = <0x20220120>;
		/* fe_ports refer to tvin.h */
		fe_ports = <0x0000a002   /* WB0_VD1 */
			0x0000a003   /* WB0_VD2 */
			0x0000a004   /* WB0_OSD1 */
			0x0000a005   /* WB0_OSD2 */
			0x0000a006   /* WB0_VPP */
			0x0000a007   /* WB0_VDIN_BIST */
			0x0000a008>; /* WB0_POST_BLEND */
		/* vdin v4l2 end */
	};

	meson-amvideom {
		compatible = "amlogic, amvideom-c5";
		dev_name = "amvideom";
		status = "okay";
		interrupts = <GIC_SPI 81 IRQ_TYPE_EDGE_RISING>;
		interrupt-names = "vsync";
	};

	lut_dma:lut_dma {
		compatible = "amlogic, meson-s5, lut_dma";
		status = "disabled";
	};

	v2d {
		compatible = "amlogic, v2d";
		dev_name = "v2d";
		status = "disabled";
	};

	videodisplay {
		compatible = "amlogic, videodisplay";
		dev_name = "videodisplay";
		status = "disabled";
	};

	video_composer {
		compatible = "amlogic, video_composer";
		vpu_dma_mask = <1>;  /* 0: <= 4G, 1: > 4G*/
		dev_name = "video_composer";
		status = "disabled";
	};

	di_process {
		compatible = "amlogic, di_process";
		dev_name = "di_process";
		status = "disabled";
	};

	vpu_security {
		compatible = "amlogic, meson-s7, vpu_security";
		dev_name = "amlogic-vpu-security";
		status = "disabled";
		interrupts = <GIC_SPI 220 IRQ_TYPE_EDGE_RISING>;
		interrupt-names = "vpu_security";
	};

	dmx_aucpu: aucpu {
		compatible = "amlogic, aucpu";
		dev_name = "aml_aucpu";
		status = "disabled";
		interrupts = <0 77 1>;
		interrupt-names = "aucpu_irq";
		reg = <0x0 0xfe09e080 0x0 0x100>;
	};

	cve:mbd_cve {
		compatible = "amlogic, cve";
		reg = <0x0 0xFF561000 0x0 0x1000>;
		reg-names = "cve";
		interrupts = <GIC_SPI 218 IRQ_TYPE_EDGE_RISING>;
		interrupt-names = "cve";
		clocks = <&clkc CLKID_CVE>, <&clkc CLKID_VGE>;
		clock-names = "clk_cve", "clk_vge";
		power-domains = <&pwrdm PDID_C5_CVE>;
		status = "okay";
	};

	ge2d {
		compatible = "amlogic, mbp-ge2d-c5";
		status = "okay";
		interrupts = <GIC_SPI 217 IRQ_TYPE_EDGE_RISING>;
		interrupt-names = "ge2d";
		clocks = <&clkc CLKID_VAPB>,
			<&clkc CLKID_GE2D>,
			<&clkc CLKID_VGE>;
		clock-names = "clk_vapb_0",
			"clk_ge2d_gate",
			"cve_arb";
		reg = <0x0 0xff560000 0x0 0x1000>;
		power-domains = <&pwrdm PDID_C5_GE2D>;
	};

	amlgdc {
		#address-cells=<2>;
		#size-cells=<2>;
		status = "okay";
		compatible = "amlogic, mbp-dewarp-v2";
		reg = <0 0xff566c00 0 0x000030c>;
		interrupts = <GIC_SPI 356 IRQ_TYPE_EDGE_RISING>,
			<GIC_SPI 374 IRQ_TYPE_EDGE_RISING>;
		interrupt-names = "amlgdc", "opp_done";
		clocks = <&clkc CLKID_DEWARPA>, <&clkc CLKID_VGE>, <&clkc CLKID_ISP0>;
		clock-names = "clk_gate", "cve_arb", "isp_clk";
		clk-rate = <800000000>;
		power-domains = <&pwrdm PDID_C5_DEWARP>;
	};

	vicp {
		compatible = "amlogic, vicp-s6";
		dev_name = "vicp";
		status = "disabled";
		interrupts = <GIC_SPI 263 IRQ_TYPE_EDGE_RISING>,
			<GIC_SPI 262 IRQ_TYPE_EDGE_RISING>,
			<GIC_SPI 261 IRQ_TYPE_EDGE_RISING>;
		interrupt-names = "vicp_err", "vicp_rdma", "vicp_proc";
		//clocks = <&clkc CLKID_VAPB_0>,
		//	<&clkc CLKID_CMPR>;
		//clock-names = "clk_vapb_0",
		//	"clk_vicp_gate";
		reg = <0x0 0xfe094000 0x0 0xe80>;
		//power-domains = <&pwrdm PDID_S6_VICP>;
	};

	aml_bt: aml_bt {
		compatible = "amlogic, aml-bt";
		status = "disabled";
	};

	aml_wifi: aml_wifi {
		compatible = "amlogic, aml-wifi";
		status = "disabled";
		wifi_pwm_tee;
		irq_trigger_type = "IRQF_TRIGGER_LOW";
		wifi_static_buf = <0>;
		//pinctrl-0 = <&pwm_e_pins>;
		//pinctrl-names = "default";
		pwm_channel1_conf {
			pwms = <&pwm_e 0 30541 0>;
			duty-cycle = <15270>;
			times = <7>;
		};
		pwm_channel2_conf {
			pwms = <&pwm_e 1 30500 0>;
			duty-cycle = <15250>;
			times = <10>;
		};
	};

	state_led: state_led {
		compatible = "amlogic,state-led-aocpu";
		mboxes = <&mbox_fifo C5_REE2AO_LED>;
		status = "disabled";
	};

	efusecheck: efusecheck{
		maincmd = <0x8200003E>;
		checknum = <3>;
		check0 = <&check_0>;
		check1 = <&check_1>;
		check2 = <&check_2>;
		check_0:check_0{
			checkname = "dgpk1";
			subcmd = <0x1000>;
		};
		check_1:check_1{
			checkname = "dgpk2";
			subcmd = <0x1001>;
		};
		check_2:check_2{
			checkname = "aud_id";
			subcmd = <0x1002>;
		};
	};
	efuse: efuse{
		compatible = "amlogic, efuse";
		reg=<0x0 0xfe440040 0x0 0x4>;
		secureboot_mask = <0x00000c00>;
		mem_size = <0x100000>;
		read_cmd = <0x82000030>;
		write_cmd = <0x82000031>;
		get_max_cmd = <0x82000033>;
		mem_in_base_cmd = <0x82000020>;
		mem_out_base_cmd = <0x82000021>;
		efuse_pattern_size = <0x600>;
		efuse_obj_cmd_status = <0x1>;
		efuse_cali_item_read = <0x1>;
		key = <&efusekey>;
		check = <&efusecheck>;
		clock-names = "efuse_clk";
		status = "okay";
	};

	efusekey:efusekey{
		keynum = <4>;
		key0 = <&key_0>;
		key1 = <&key_1>;
		key2 = <&key_2>;
		key3 = <&key_3>;
		key_0:key_0{
			keyname = "mac";
			offset = <0>;
			size = <6>;
		};
		key_1:key_1{
			keyname = "mac_bt";
			offset = <6>;
			size = <6>;
		};
		key_2:key_2{
			keyname = "mac_wifi";
			offset = <12>;
			size = <6>;
		};
		key_3:key_3{
			keyname = "usid";
			offset = <18>;
			size = <16>;
		};
	};

	aml_mkl {
		compatible = "amlogic,aml_mkl";
		reg = <0x0 0xfe440200 0x0 0xf0>;
		kl_type = <1>;
		kl_vid_type = <0>;
		kl_offset = <0x80 0x88 0x8c 0x90>;
		status = "okay";
	};

	aml_kt {
		compatible = "amlogic,aml_kt";
		reg = <0x0 0xfe440500 0x0 0xa0>;
		kt_offset = <0x80 0x88 0x8c 0x90 0x94 0x98 0x9c>;
		kt_cap = <0x2007 0x3f 0 16 0 32>;
		kt_reserved = <0>;
		kt_host_key_max_len = <32>;
		status = "okay";
	};

	chosen:chosen {
		bootargs = "usbcore.autosuspend=-1 dm_mod.reserved_bio_based_ios=8";
	};

	gpu_opp_table: gpu_opp_table {
		compatible = "operating-points-v2";
		opp-285 {
			opp-hz = /bits/ 64 <285714281>;
			opp-microvolt = <1150>;
		};
		opp-400 {
			opp-hz = /bits/ 64 <400000000>;
			opp-microvolt = <1150>;
		};
		opp-500 {
			opp-hz = /bits/ 64 <500000000>;
			opp-microvolt = <1150>;
		};
		opp-666 {
			opp-hz = /bits/ 64 <666666666>;
			opp-microvolt = <1150>;
		};
		opp-800 {
			opp-hz = /bits/ 64 <800000000>;
			opp-microvolt = <1150>;
		};
		opp-996 {
			opp-hz = /bits/ 64 <996000000>;
			opp-microvolt = <1150>;
		};
	};

	smmu: aml_smmu {
		compatible = "amlogic,smmu";
		status = "disabled";
		#iommu-cells = <1>;
		//memory-region = <&pcie_dma_ops_mm>;
	};

	codec_mm {
		compatible = "amlogic, codec, mm";
		memory-region = <&codec_mm_cma>;
		dev_name = "codec_mm";
		status = "okay";
		/*
		 * scatter_alloc_mode: the mode of scatter memory allocation
		 * 0: default mode, alloc from system and cma
		 * 1: only alloc from system
		 */
		scatter_alloc_mode = <1>;
	};
	encmem_rev {
		compatible = "encmem_rev";
		dev_name = "encmem";
		status = "disabled";
	};
	amdolby_vision {
		compatible = "amlogic, dolby_vision_s6";
		dev_name = "aml_amdolby_vision_driver";
		status = "disabled";
		tv_mode = <0>;/*1:enable ;0:disable*/
	};

	cvbsout {
		compatible = "amlogic, cvbsout-s4";
		status = "disabled";

		/* clk path */
		/* 0:vid_pll vid2_clk */
		/* 1:gp0_pll vid2_clk */
		/* 2:vid_pll vid1_clk */
		/* 3:gp0_pll vid1_clk */
		clk_path = <0>;

		/* performance: reg_address, reg_value */
		/* s4 */
		performance_pal = <0x1bf0  0x9 /* default Matrx625 CTCC value*/
			0x1b12  0x80c0
			0x1b05  0xf7
			0x1b56  0x333
			0x1c59  0xf25c
			0xffff  0x0>; /* ending flag */
		performance = <0x1bf0  0x9 /* ccitt033 SVA value */
			0x1b12  0x8040
			0x1b05  0xfd
			0x1b56  0x333
			0x1c59  0xf654
			0xffff  0x0>; /* ending flag */
		performance_ntsc = <0x1bf0  0x9
			0x1b12  0x8020
			0x1b03  0x0
			0x1b04  0x0
			0x1b05  0x0
			0x1b06  0x0
			0x1b56  0x333
			0x1c59  0xf850
			0xffff  0x0>; /* ending flag */
	};

	ionvideo {
		compatible = "amlogic, ionvideo";
		dev_name = "ionvideo";
		status = "disabled";
	};

	amlvideo2_0: amlvideo2_0 {
		compatible = "amlogic, amlvideo2";
		dev_name = "amlvideo2";
		vpu_dma_mask = <1>;  /* 0: <= 4G, 1: > 4G*/
		status = "disabled";
		amlvideo2_id = <0>;
		cma_mode = <1>;
	};

	amlvideo2_1: amlvideo2_1 {
		compatible = "amlogic, amlvideo2";
		dev_name = "amlvideo2";
		vpu_dma_mask = <1>;  /* 0: <= 4G, 1: > 4G*/
		status = "disabled";
		amlvideo2_id = <1>;
		cma_mode = <1>;
		/*720P_NV21:1, 1080P_NV21:2, 4K_NV21:3, default:4*/
		codec_mm_alloc = <1>;
	};

	amvdec_csi: amvdec_csi {
		compatible = "amlogic, amvdec_csi-s6";
		status = "disabled";
		csi_id = <0>;
		squlech_mode = <0>;
		deskew_mode = <0>;
		reg = <0x0 0xfe014000 0x0 0x00000100>,
			<0x0 0xfe016000 0x0 0x00000100>,
			<0x0 0xfe018000 0x0 0x00000100>;
		reg-names = "csi_phy", "csi_host", "csi_adapt";

		//clocks = <&clkc CLKID_CSI2_ADAPT>,
		//	<&clkc CLKID_MIPI_CSI_PHY_0>;
		//clock-names = "cts_csi_adapt_clk_composite",
		//	"cts_csi_phy_clk_composite";

		// depends on power domain.
		//power-domains = <&pwrdm PDID_S6_ADAPT>;

		// 88 for csi2_adap_int
		interrupts = <GIC_SPI 88 IRQ_TYPE_EDGE_RISING>;
		interrupt-names = "csi_phy";
	};

	ppmgr {
		compatible = "amlogic, ppmgr";
		//memory-region = <&ppmgr_reserved>;
		dev_name = "ppmgr";
		status = "disabled";
	};

	provisionkey {
		compatible = "amlogic, provisionkey";
		status = "disabled";
		key-permit-default = "write";
		//new key not need add dts if started with KEY_PROVISION_
		KEY_PROVISION_XXX { };
		//test_my_added_keyname { };
	};//End provisionkey

	unifykey{
		compatible = "amlogic,unifykey";
		status = "okay";
		unifykey-num = <19>;
		unifykey-index-0 = <&keysn_0>;
		unifykey-index-1 = <&keysn_1>;
		unifykey-index-2 = <&keysn_2>;
		unifykey-index-3 = <&keysn_3>;
		unifykey-index-4 = <&keysn_4>;
		unifykey-index-5 = <&keysn_5>;
		unifykey-index-6 = <&keysn_6>;
		unifykey-index-7 = <&keysn_7>;
		unifykey-index-8 = <&keysn_8>;
		unifykey-index-9 = <&keysn_9>;
		unifykey-index-10= <&keysn_10>;
		unifykey-index-11= <&keysn_11>;
		unifykey-index-12= <&keysn_12>;
		unifykey-index-13= <&keysn_13>;
		unifykey-index-14= <&keysn_14>;
		unifykey-index-15= <&keysn_15>;
		unifykey-index-16= <&keysn_16>;
		unifykey-index-17= <&keysn_17>;
		unifykey-index-18= <&keysn_18>;

		keysn_0: key_0{
			key-name = "usid";
			key-device = "normal";
			key-permit = "read","write","del";
		};
		keysn_1:key_1{
			key-name = "mac";
			key-device = "normal";
			key-permit = "read","write","del";
		};
		keysn_2:key_2{
			key-name = "hdcp";
			key-device = "secure";
			key-type = "sha1";
			key-permit = "read","write","del";
		};
		keysn_3:key_3{
			key-name = "secure_boot_set";
			key-device = "efuse";
			key-permit = "write";
		};
		keysn_4:key_4{
			key-name = "mac_bt";
			key-device = "normal";
			key-permit = "read","write","del";
			key-type  = "mac";
		};
		keysn_5:key_5{
			key-name = "mac_wifi";
			key-device = "normal";
			key-permit = "read","write","del";
			key-type = "mac";
		};
		keysn_6:key_6{
			key-name = "hdcp2_tx";
			key-device = "normal";
			key-permit = "read","write","del";
		};
		keysn_7:key_7{
			key-name = "hdcp2_rx";
			key-device = "normal";
			key-permit = "read","write","del";
		};
		keysn_8:key_8{
			key-name = "widevinekeybox";
			key-device = "secure";
			key-permit = "read","write","del";
		};
		keysn_9:key_9{
			key-name = "deviceid";
			key-device = "normal";
			key-permit = "read","write","del";
		};
		keysn_10:key_10{
			key-name = "hdcp22_fw_private";
			key-device = "secure";
			key-permit = "read","write","del";
		};
		keysn_11:key_11{
			key-name = "PlayReadykeybox25";
			key-device = "secure";
			key-permit = "read","write","del";
		};
		keysn_12:key_12{
			key-name = "prpubkeybox";//PlayReady
			key-device = "secure";
			key-permit = "read","write","del";
		};
		keysn_13:key_13{
			key-name = "prprivkeybox";//PlayReady
			key-device = "secure";
			key-permit = "read","write","del";
		};
		keysn_14:key_14{
			key-name = "attestationkeybox";//attestation key
			key-device = "secure";
			key-permit = "read","write","del";
		};
		keysn_15:key_15{
			key-name = "region_code";
			key-device = "normal";
			key-permit = "read","write","del";
		};
		keysn_16:key_16{
			key-name = "netflix_mgkid";
			key-device = "secure";
			key-permit = "read","write","del";
		};
		keysn_17:key_17{
			key-name = "attestationdevidbox";//attest dev id box
			key-device = "secure";
			key-permit = "read","write","del";
		};
		keysn_18:key_18{
			key-name = "oemkey";
			key-device = "normal";
			key-permit = "read","write","del";
		};
	};//End unifykey

	freertos: freertos {
		compatible = "amlogic,freertos";
		status = "disabled";
		irqs_rsv = <32 177>;
	};

	picdec {
		compatible = "amlogic, picdec";
		status = "disabled";
	};
};

&ao_pinctrl {

	i2c0_ao_pins1:i2c0_pins1 {
		mux {
			groups = "i2c0_ao_sck",
				"i2c0_ao_sda";
			function = "i2c0_ao";
			bias-disable;
		};
	};

	i2c0_ao_pins1_sleep:i2c0_ao_pins1_sleep {
		mux {
			groups = "GPIOAO_0",
				"GPIOAO_1";
			function = "gpio_ao";
			input-enable;
		};
	};

	i2c1_ao_pins1:i2c1_ao_pins1 {
		mux {
			groups = "i2c1_ao_sck_ao6",
				"i2c1_ao_sda_ao7";
			function = "i2c1_ao";
			bias-disable;
		};
	};

	i2c1_ao_pins1_sleep:i2c1_ao_pins1_sleep {
		mux {
			groups = "GPIOAO_6",
				"GPIOAO_7";
			function = "gpio_ao";
			input-enable;
		};
	};

	i2c1_ao_pins2:i2c1_ao_pins2 {
		mux {
			groups = "i2c1_ao_sck_ao15",
				"i2c1_ao_sda_ao16";
			function = "i2c1_ao";
			bias-disable;
		};
	};

	i2c1_ao_pins2_sleep:i2c1_ao_pins2_sleep {
		mux {
			groups = "GPIOAO_15",
				"GPIOAO_16";
			function = "gpio_ao";
			input-enable;
		};
	};

	i2c1_ao_pins3:i2c1_ao_pins3 {
		mux {
			groups = "i2c1_ao_sck_f",
				"i2c1_ao_sda_f";
			function = "i2c1_ao";
			bias-disable;
		};
	};

	i2c1_ao_pins3_sleep:i2c1_ao_pins3_sleep {
		mux {
			groups = "GPIOF_2",
				"GPIOF_3";
			function = "gpio_ao";
			input-enable;
		};
	};

	i2c2_ao_pins1:i2c2_ao_pins1 {
		mux {
			groups = "i2c2_sck_p",
				"i2c2_sda_p";
			function = "i2c2_ao";
			bias-disable;
		};
	};

	i2c2_ao_pins1_sleep:i2c2_ao_pins1_sleep {
		mux {
			groups = "GPIOP_0",
				"GPIOP_1";
			function = "gpio_ao";
			input-enable;
		};
	};

	i2c2_ao_pins2:i2c2_ao_pins2 {
		mux {
			groups = "i2c2_sck_ao",
				"i2c2_sda_ao";
			function = "i2c2_ao";
			bias-disable;
		};
	};

	i2c2_ao_pins2_sleep:i2c2_ao_pins2_sleep {
		mux {
			groups = "GPIOAO_21",
				"GPIOAO_22";
			function = "gpio_ao";
			input-enable;
		};
	};

	i2c3_ao_pins1:i2c3_ao_pins1 {
		mux {
			groups = "i2c3_sck_p",
				"i2c3_sda_p";
			function = "i2c3_ao";
			bias-disable;
		};
	};

	i2c3_ao_pins1_sleep:i2c3_ao_pins1_sleep {
		mux {
			groups = "GPIOP_2",
				"GPIOP_3";
			function = "gpio_ao";
			input-enable;
		};
	};

	i2c4_ao_pins1:i2c4_ao_pins1 {
		mux {
			groups = "i2c4_sck_p",
				"i2c4_sda_p";
			function = "i2c4_ao";
			bias-disable;
		};
	};

	i2c4_ao_pins1_sleep:i2c4_ao_pins1_sleep {
		mux {
			groups = "GPIOP_4",
				"GPIOP_5";
			function = "gpio_ao";
			input-enable;
		};
	};

	i2c5_ao_pins1:i2c5_ao_pins1 {
		mux {
			groups = "i2c5_sck_p",
				"i2c5_sda_p";
			function = "i2c5_ao";
			bias-disable;
		};
	};

	i2c5_ao_pins1_sleep:i2c5_ao_pins1_sleep {
		mux {
			groups = "GPIOP_6",
				"GPIOP_7";
			function = "gpio_ao";
			input-enable;
		};
	};

	i2c6_ao_pins1:i2c6_ao_pins1 {
		mux {
			groups = "i2c6_sck_p",
				"i2c6_sda_p";
			function = "i2c6_ao";
			bias-disable;
		};
	};

	i2c6_ao_pins1_sleep:i2c6_ao_pins1_sleep {
		mux {
			groups = "GPIOP_8",
				"GPIOP_9";
			function = "gpio_ao";
			input-enable;
		};
	};

	pwm_a_ao_pins1: pwm_a_ao_pins1 {
		mux {
			groups = "pwm_ao_a_testn";
			function = "pwm_ao_a";
		};
	};

	pwm_a_ao_pins1_sleep: pwm_a_ao_pins1_sleep {
		mux {
			groups = "GPIO_TEST_N";
			function = "gpio_ao";
			input-enable;
		};
	};

	pwm_a_ao_pins2: pwm_a_ao_pins2 {
		mux {
			groups = "pwm_ao_a_f";
			function = "pwm_ao_a";
		};
	};

	pwm_a_ao_pins2_sleep: pwm_a_ao_pins2_sleep {
		mux {
			groups = "GPIOF_2";
			function = "gpio_ao";
			input-enable;
		};
	};

	pwm_a_ao_pins3: pwm_a_ao_pins3 {
		mux {
			groups = "pwm_ao_a_p";
			function = "pwm_ao_a";
		};
	};

	pwm_a_ao_pins3_sleep: pwm_a_ao_pins3_sleep {
		mux {
			groups = "GPIOP_12";
			function = "gpio_ao";
			input-enable;
		};
	};

	pwm_b_ao_pins1: pwm_b_ao_pins1 {
		mux {
			groups = "pwm_ao_b_f";
			function = "pwm_ao_b";
		};
	};

	pwm_b_ao_pins1_sleep: pwm_b_ao_pins1_sleep {
		mux {
			groups = "GPIOF_3";
			function = "gpio_ao";
			input-enable;
		};
	};

	pwm_b_ao_pins2: pwm_b_ao_pins2 {
		mux {
			groups = "pwm_ao_b_p";
			function = "pwm_ao_b";
		};
	};

	pwm_b_ao_pins2_sleep: pwm_b_ao_pins2_sleep {
		mux {
			groups = "GPIOP_13";
			function = "gpio_ao";
			input-enable;
		};
	};

	pwm_b_ao_pins3: pwm_b_ao_pins3 {
		mux {
			groups = "pwm_ao_b_ao10";
			function = "pwm_ao_b";
		};
	};

	pwm_b_ao_pins3_sleep: pwm_b_ao_pins3_sleep {
		mux {
			groups = "GPIOAO_10";
			function = "gpio_ao";
			input-enable;
		};
	};

	pwm_b_ao_pins4: pwm_b_ao_pins4 {
		mux {
			groups = "pwm_ao_b_ao7";
			function = "pwm_ao_b";
		};
	};

	pwm_b_ao_pins4_sleep: pwm_b_ao_pins4_sleep {
		mux {
			groups = "GPIOAO_7";
			function = "gpio_ao";
			input-enable;
		};
	};

	pwm_k_ao_pins1: pwm_k_ao_pins1 {
		mux {
			groups = "pwm_k_f";
			function = "pwm_ao_k";
		};
	};

	pwm_k_ao_pins1_sleep: pwm_k_ao_pins1_sleep {
		mux {
			groups = "GPIOF_4";
			function = "gpio_ao";
			input-enable;
		};
	};

	pwm_k_ao_pins2: pwm_k_ao_pins2 {
		mux {
			groups = "pwm_k_p";
			function = "pwm_ao_k";
		};
	};

	pwm_k_ao_pins2_sleep: pwm_k_ao_pins2_sleep {
		mux {
			groups = "GPIOP_0";
			function = "gpio_ao";
			input-enable;
		};
	};

	pwm_l_ao_pins1: pwm_l_ao_pins1 {
		mux {
			groups = "pwm_l_f";
			function = "pwm_ao_l";
		};
	};

	pwm_l_ao_pins1_sleep: pwm_l_ao_pins1_sleep {
		mux {
			groups = "GPIOF_5";
			function = "gpio_ao";
			input-enable;
		};
	};

	pwm_l_ao_pins2: pwm_l_ao_pins2 {
		mux {
			groups = "pwm_l_p";
			function = "pwm_ao_l";
		};
	};

	pwm_l_ao_pins2_sleep: pwm_l_ao_pins2_sleep {
		mux {
			groups = "GPIOP_1";
			function = "gpio_ao";
			input-enable;
		};
	};

	pwm_m_ao_pins1: pwm_m_ao_pins1 {
		mux {
			groups = "pwm_m_f";
			function = "pwm_ao_m";
		};
	};

	pwm_m_ao_pins1_sleep: pwm_m_ao_pins1_sleep {
		mux {
			groups = "GPIOF_6";
			function = "gpio_ao";
			input-enable;
		};
	};

	pwm_m_ao_pins2: pwm_m_ao_pins2 {
		mux {
			groups = "pwm_m_p";
			function = "pwm_ao_m";
		};
	};

	pwm_m_ao_pins2_sleep: pwm_m_ao_pins2_sleep {
		mux {
			groups = "GPIOP_2";
			function = "gpio_ao";
			input-enable;
		};
	};

	pwm_m_ao_pins3: pwm_m_ao_pins3 {
		mux {
			groups = "pwm_m_ao";
			function = "pwm_ao_m";
		};
	};

	pwm_m_ao_pins3_sleep: pwm_m_ao_pins3_sleep {
		mux {
			groups = "GPIOAO_4";
			function = "gpio_ao";
			input-enable;
		};
	};

	pwm_n_ao_pins1: pwm_n_ao_pins1 {
		mux {
			groups = "pwm_n_p";
			function = "pwm_ao_n";
		};
	};

	pwm_n_ao_pins1_sleep: pwm_n_ao_pins1_sleep {
		mux {
			groups = "GPIOP_3";
			function = "gpio_ao";
			input-enable;
		};
	};

	pwm_n_ao_pins2: pwm_n_ao_pins2 {
		mux {
			groups = "pwm_n_ao";
			function = "pwm_ao_n";
		};
	};

	pwm_n_ao_pins2_sleep: pwm_n_ao_pins2_sleep {
		mux {
			groups = "GPIOAO_5";
			function = "gpio_ao";
			input-enable;
		};
	};

	pwm_o_ao_pins1: pwm_o_ao_pins1 {
		mux {
			groups = "pwm_o_p";
			function = "pwm_ao_o";
		};
	};

	pwm_o_ao_pins1_sleep: pwm_o_ao_pins1_sleep {
		mux {
			groups = "GPIOP_4";
			function = "gpio_ao";
			input-enable;
		};
	};

	pwm_o_ao_pins2: pwm_o_ao_pins2 {
		mux {
			groups = "pwm_o_ao";
			function = "pwm_ao_o";
		};
	};

	pwm_o_ao_pins2_sleep: pwm_o_ao_pins2_sleep {
		mux {
			groups = "GPIOAO_6";
			function = "gpio_ao";
			input-enable;
		};
	};

	pwm_p_ao_pins1: pwm_p_ao_pins1 {
		mux {
			groups = "pwm_p_p";
			function = "pwm_ao_p";
		};
	};

	pwm_p_ao_pins1_sleep: pwm_p_ao_pins1_sleep {
		mux {
			groups = "GPIOP_5";
			function = "gpio_ao";
			input-enable;
		};
	};

	pwm_p_ao_pins2: pwm_p_ao_pins2 {
		mux {
			groups = "pwm_p_ao";
			function = "pwm_ao_p";
		};
	};

	pwm_p_ao_pins2_sleep: pwm_p_ao_pins2_sleep {
		mux {
			groups = "GPIOAO_7";
			function = "gpio_ao";
			input-enable;
		};
	};
	pwm_q_ao_pins1: pwm_q_ao_pins1 {
		mux {
			groups = "pwm_q_p";
			function = "pwm_ao_q";
		};
	};

	pwm_q_ao_pins1_sleep: pwm_q_ao_pins1_sleep {
		mux {
			groups = "GPIOP_6";
			function = "gpio_ao";
			input-enable;
		};
	};

	pwm_q_ao_pins2: pwm_q_ao_pins2 {
		mux {
			groups = "pwm_q_ao";
			function = "pwm_ao_q";
		};
	};

	pwm_q_ao_pins2_sleep: pwm_q_ao_pins2_sleep {
		mux {
			groups = "GPIOAO_8";
			function = "gpio_ao";
			input-enable;
		};
	};

	pwm_r_ao_pins1: pwm_r_ao_pins1 {
		mux {
			groups = "pwm_r_p";
			function = "pwm_ao_r";
		};
	};

	pwm_r_ao_pins1_sleep: pwm_r_ao_pins1_sleep {
		mux {
			groups = "GPIOP_7";
			function = "gpio_ao";
			input-enable;
		};
	};

	pwm_r_ao_pins2: pwm_r_ao_pins2 {
		mux {
			groups = "pwm_r_ao";
			function = "pwm_ao_r";
		};
	};

	pwm_s_ao_pins1: pwm_s_ao_pins1 {
		mux {
			groups = "pwm_s_p";
			function = "pwm_ao_s";
		};
	};

	pwm_s_ao_pins1_sleep: pwm_s_ao_pins1_sleep {
		mux {
			groups = "GPIOP_8";
			function = "gpio_ao";
			input-enable;
		};
	};

	pwm_s_ao_pins2: pwm_s_ao_pins2 {
		mux {
			groups = "pwm_s_ao";
			function = "pwm_ao_s";
		};
	};

	pwm_s_ao_pins2_sleep: pwm_s_ao_pins2_sleep {
		mux {
			groups = "GPIOAO_11";
			function = "gpio_ao";
			input-enable;
		};
	};

	pwm_t_ao_pins1: pwm_t_ao_pins1 {
		mux {
			groups = "pwm_t_p";
			function = "pwm_ao_t";
		};
	};

	pwm_t_ao_pins1_sleep: pwm_t_ao_pins1_sleep {
		mux {
			groups = "GPIOP_9";
			function = "gpio_ao";
			input-enable;
		};
	};

	eth_pins: eth {
		mux {
			groups = "eth_a_mdio",
				 "eth_a_mdc",
				 "eth_a_rgmii_rx_clk",
				 "eth_a_rx_dv",
				 "eth_a_rxd0",
				 "eth_a_rxd1",
				 "eth_a_txen",
				 "eth_a_txd0",
				 "eth_a_txd1";
			function = "eth";
			drive-strength-microamp = <3000>;
			bias-disable;
		};
	};

	eth_rgmii_pins: eth-rgmii {
		mux {
			groups = "eth_a_rxd2_rgmii",
				 "eth_a_rxd3_rgmii",
				 "eth_a_rgmii_tx_clk",
				 "eth_a_txd2_rgmii",
				 "eth_a_txd3_rgmii";
			function = "eth";
			drive-strength-microamp = <3000>;
			bias-disable;
		};
	};

	remote_pins: remote_pin {
		mux {
			groups = "ir_ao_in";
			function = "ir_ao_in";
			bias-disable;
		};
	};

	ao_a_uart_pins:ao_a_uart {
		mux {
			groups = "uart_ao_a_tx_f",
				"uart_ao_a_rx_f";
			function = "uart_ao_a";
			drive-strength = <3>;
			bias-pull-up;
		};
	};

	ao_a_uart_pins1:ao_a_uart1 {
		mux {
			groups = "uart_ao_a_tx_p",
				"uart_ao_a_rx_p",
				"uart_ao_a_cts_p",
				"uart_ao_a_rts_p";
			function = "uart_ao_a";
			drive-strength = <3>;
			bias-pull-up;
		};
	};

	ao_a_uart_pins2:ao_a_uart2 {
		mux {
			groups = "uart_ao_a_tx_ao",
				"uart_ao_a_rx_ao",
				"uart_ao_a_cts_ao",
				"uart_ao_a_rts_ao";
			function = "uart_ao_a";
			drive-strength = <3>;
			bias-pull-up;
		};
	};

	ao_b_uart_pins:ao_b_uart {
		mux {
			groups = "uart_ao_b_tx_f",
				"uart_ao_b_rx_f";
			function = "uart_ao_b";
			drive-strength = <3>;
			bias-pull-up;
		};
	};

	ao_f_uart_pins:ao_f_uart {
		mux {
			groups = "uart_f_tx_p",
				"uart_f_rx_p";
			function = "uart_ao_f";
			drive-strength = <3>;
			bias-pull-up;
		};
	};

	ao_e_uart_pins:ao_e_uart {
		mux {
			groups = "uart_e_tx_p",
				"uart_e_rx_p";
			function = "uart_ao_e";
			drive-strength = <3>;
			bias-pull-up;
		};
	};
};

&periphs_pinctrl {
	bl_pwm_off_pins:bl_pwm_off_pin {
		mux {
			groups = "GPIOF_4";
			function = "gpio_periphs";
			drive-strength = <3>;
			bias-pull-up;
		};
	};

	i2c2_pins1:i2c2_pins1 {
		mux {
			groups = "i2c2_sck_x",
				"i2c2_sda_x";
			function = "i2c2";
			bias-disable;
		};
	};

	i2c2_pins1_sleep:i2c2_pins1_sleep {
		mux {
			groups = "GPIOX_0",
				"GPIOX_1";
			function = "gpio_periphs";
			input-enable;
		};
	};

	i2c2_pins2:i2c2_pins2 {
		mux {
			groups = "i2c2_sck_dsi",
				"i2c2_sda_dsi";
			function = "i2c2";
			bias-disable;
		};
	};

	i2c2_pins2_sleep:i2c2_pins2_sleep {
		mux {
			groups = "GPIODSI_0",
				"GPIODSI_1";
			function = "gpio_periphs";
			input-enable;
		};
	};

	i2c3_pins1:i2c3_pins1 {
		mux {
			groups = "i2c3_sck_d",
				"i2c3_sda_d";
			function = "i2c3";
			bias-disable;
		};
	};

	i2c3_pins1_sleep:i2c3_pins1_sleep {
		mux {
			groups = "GPIOD_8",
				"GPIOD_9";
			function = "gpio_periphs";
			input-enable;
		};
	};

	i2c3_pins2:i2c3_pins2 {
		mux {
			groups = "i2c3_sck_x",
				"i2c3_sda_x";
			function = "i2c3";
			bias-disable;
		};
	};

	i2c3_pins2_sleep:i2c3_pins2_sleep {
		mux {
			groups = "GPIOX_12",
				"GPIOX_13";
			function = "gpio_periphs";
			input-enable;
		};
	};

	i2c3_pins3:i2c3_pins3 {
		mux {
			groups = "i2c3_sck_a",
				"i2c3_sda_a";
			function = "i2c3";
			bias-disable;
		};
	};

	i2c3_pins3_sleep:i2c3_pins3_sleep {
		mux {
			groups = "GPIOA_5",
				"GPIOA_5";
			function = "gpio_periphs";
			input-enable;
		};
	};

	i2c3_pins4:i2c3_pins4 {
		mux {
			groups = "i2c3_sck_dsi",
				"i2c3_sda_dsi";
			function = "i2c3";
			bias-disable;
		};
	};

	i2c3_pins4_sleep:i2c3_pins4_sleep {
		mux {
			groups = "GPIODSI_2",
				"GPIODSI_3";
			function = "gpio_periphs";
			input-enable;
		};
	};

	i2c4_pins1:i2c4_pins1 {
		mux {
			groups = "i2c4_sck_x",
				"i2c4_sda_x";
			function = "i2c4";
			bias-disable;
		};
	};

	i2c4_pins1_sleep:i2c4_pins1_sleep {
		mux {
			groups = "GPIOP_4",
				"GPIOP_5";
			function = "gpio_periphs";
			input-enable;
		};
	};

	i2c4_pins2:i2c4_pins2 {
		mux {
			groups = "i2c4_sck_dsi",
				"i2c4_sda_dsi";
			function = "i2c4";
			bias-disable;
		};
	};

	i2c4_pins2_sleep:i2c4_pins2_sleep {
		mux {
			groups = "GPIODSI_4",
				"GPIODSI_5";
			function = "gpio_periphs";
			input-enable;
		};
	};

	i2c5_pins1:i2c5_pins1 {
		mux {
			groups = "i2c5_sck_b",
				"i2c5_sda_b";
			function = "i2c5";
			bias-disable;
		};
	};

	i2c5_pins1_sleep:i2c5_pins1_sleep {
		mux {
			groups = "GPIOB_5",
				"GPIOB_6";
			function = "gpio_periphs";
			input-enable;
		};
	};

	i2c5_pins2:i2c5_pins2 {
		mux {
			groups = "i2c5_sck_c",
				"i2c5_sda_c";
			function = "i2c5";
			bias-disable;
		};
	};

	i2c5_pins2_sleep:i2c5_pins2_sleep {
		mux {
			groups = "GPIOC_5",
				"GPIOC_6";
			function = "gpio_periphs";
			input-enable;
		};
	};

	i2c5_pins3:i2c5_pins3 {
		mux {
			groups = "i2c5_sck_x",
				"i2c5_sda_x";
			function = "i2c5";
			bias-disable;
		};
	};

	i2c5_pins3_sleep:i2c5_pins3_sleep {
		mux {
			groups = "GPIOX_6",
				"GPIOX_7";
			function = "gpio_periphs";
			input-enable;
		};
	};

	i2c5_pins4:i2c5_pins4 {
		mux {
			groups = "i2c5_sck_dsi",
				"i2c5_sda_dsi";
			function = "i2c5";
			bias-disable;
		};
	};

	i2c5_pins4_sleep:i2c5_pins4_sleep {
		mux {
			groups = "GPIODSI_6",
				"GPIODSI_7";
			function = "gpio_periphs";
			input-enable;
		};
	};

	i2c6_pins1:i2c6_pins1 {
		mux {
			groups = "i2c6_sck_b",
				"i2c6_sda_b";
			function = "i2c6";
			bias-disable;
		};
	};

	i2c6_pins1_sleep:i2c6_pins1_sleep {
		mux {
			groups = "GPIOB_11",
				"GPIOB_12";
			function = "gpio_periphs";
			input-enable;
		};
	};

	i2c6_pins2:i2c6_pins2 {
		mux {
			groups = "i2c6_sck_x2",
				"i2c6_sda_x3";
			function = "i2c6";
			bias-disable;
		};
	};

	i2c6_pins2_sleep:i2c6_pins2_sleep {
		mux {
			groups = "GPIOX_2",
				"GPIOX_3";
			function = "gpio_periphs";
			input-enable;
		};
	};

	i2c6_pins3:i2c6_pins3 {
		mux {
			groups = "i2c6_sck_x8",
				"i2c6_sda_x9";
			function = "i2c6";
			bias-disable;
		};
	};

	i2c6_pins3_sleep:i2c6_pins3_sleep {
		mux {
			groups = "GPIOX_8",
				"GPIOX_9";
			function = "gpio_periphs";
			input-enable;
		};
	};

	i2c6_pins4:i2c6_pins4 {
		mux {
			groups = "i2c6_sck_dsi",
				"i2c6_sda_dsi";
			function = "i2c6";
			bias-disable;
		};
	};

	i2c6_pins4_sleep:i2c6_pins4_sleep {
		mux {
			groups = "GPIODSI_8",
				"GPIODSI_9";
			function = "gpio_periphs";
			input-enable;
		};
	};

	b_uart_pins:b_uart {
		mux {
			groups = "uart_b_tx",
				"uart_b_rx";
			function = "uart_b";
			drive-strength = <3>;
			bias-pull-up;
		};
	};

	c_uart_pins:c_uart {
		mux {
			groups = "uart_c_cts_b",
				"uart_c_rts_b",
				"uart_c_tx_b",
				"uart_c_rx_b";
			function = "uart_c";
			drive-strength = <3>;
			bias-pull-up;
		};
	};

	c_uart_pins1:c_uart1 {
		mux {
			groups = "uart_c_tx_c",
				"uart_c_rx_c";
			function = "uart_c";
			drive-strength = <3>;
			bias-pull-up;
		};
	};

	c_uart_pins2:c_uart2 {
		mux {
			groups = "uart_c_tx_d",
				"uart_c_rx_d";
			function = "uart_c";
			drive-strength = <3>;
			bias-pull-up;
		};
	};

	d_uart_pins:d_uart {
		mux {
			groups = "uart_d_tx_d",
				"uart_d_tx_d";
			function = "uart_d";
			drive-strength = <3>;
			bias-pull-up;
		};
	};

	d_uart_pins1:d_uart1 {
		mux {
			groups = "uart_d_tx_x",
				"uart_d_rx_x",
				"uart_d_cts_x",
				"uart_d_rts_x";
			function = "uart_d";
			drive-strength = <3>;
			bias-pull-up;
		};
	};

	d_uart_pins2:d_uart2 {
		mux {
			groups = "uart_d_tx_c",
				"uart_d_tx_c";
			function = "uart_d";
			drive-strength = <3>;
			bias-pull-up;
		};
	};

	e_uart_pins:e_uart {
		mux {
			groups = "uart_e_rx_d",
				"uart_e_tx_d";
			function = "uart_e";
			drive-strength = <3>;
			bias-pull-up;
		};
	};

	e_uart_pins1:e_uart1 {
		mux {
			groups = "uart_e_tx_x",
				"uart_e_rx_x",
				"uart_e_cts_x",
				"uart_e_rts_x";
			function = "uart_e";
			drive-strength = <3>;
			bias-pull-up;
		};
	};

	f_uart_pins:f_uart {
		mux {
			groups = "uart_f_rx_d",
				"uart_f_tx_d";
			function = "uart_f";
			drive-strength = <3>;
			bias-pull-up;
		};
	};

	f_uart_pins1:f_uart1 {
		mux {
			groups = "uart_f_tx_x",
				"uart_f_rx_x",
				"uart_f_cts_x",
				"uart_f_rts_x";
			function = "uart_f";
			drive-strength = <3>;
			bias-pull-up;
		};
	};

	emmc_pins: emmc_pins {
		mux-0 {
			groups = "emmc_d0",
				 "emmc_d1",
				 "emmc_d2",
				 "emmc_d3",
				 "emmc_d4",
				 "emmc_d5",
				 "emmc_d6",
				 "emmc_d7",
				 "emmc_cmd";
			function = "emmc";
			bias-pull-up;
			drive-strength-microamp = <3000>;
		};

		mux-1 {
			groups = "emmc_clk";
			function = "emmc";
			bias-pull-up;
			drive-strength-microamp = <3000>;
		};
	};

	emmc_ds_pins: emmc_ds_pins {
		mux {
			groups = "emmc_ds";
			function = "emmc";
			bias-pull-down;
			drive-strength-microamp = <3000>;
		};
	};

	emmc_clk_gate_pins: emmc_clk_gate_pins {
		mux {
			groups = "GPIOB_8";
			function = "gpio_periphs";
			bias-pull-down;
			drive-strength-microamp = <3000>;
		};
	};

	all_nand_pins: all_nand_pins {
	mux {
			groups = "emmc_nand_d0",
				"emmc_nand_d1",
				"emmc_nand_d2",
				"emmc_nand_d3",
				"emmc_nand_d4",
				"emmc_nand_d5",
				"emmc_nand_d6",
				"emmc_nand_d7",
				"nand_ce0",
				"nand_ale",
				"nand_cle",
				"nand_wen_clk",
				"nand_ren_wr";
			function = "nand";
			input-enable;
		};
	};

	nand_cs_pins: nand_cs {
		mux {
			groups = "nand_ce0";
			function = "nand";
		};
	};

	sd_to_ao_uart_clr_pins: sd_to_ao_uart_clr_pins {
		mux {
			groups = "GPIOD_0",
				   "GPIOD_1";
			function = "gpio_periphs";
		};
	};

	sdcard_pins: sdcard_pins {
		mux {
			groups = "sdcard_d0",
				 "sdcard_d1",
				 "sdcard_d2",
				 "sdcard_d3",
				 "sdcard_clk",
				 "sdcard_cmd";
			function = "sdcard";
			bias-pull-up;
			drive-strength-microamp = <3000>;
		};
	};

	ao_to_sd_uart_pins: ao_to_sd_uart_pins {
		mux {
			groups = "uart_b_tx_c",
				"uart_b_rx_c";
			function = "uart_b";
			bias-pull-up;
			input-enable;
		};
	};

	sd_clr_all_pins: sd_clr_all_pins {
		mux {
			groups = "GPIOC_0",
				   "GPIOC_1",
				   "GPIOC_2",
				   "GPIOC_3",
				   "GPIOC_5";
			function = "gpio_periphs";
			output-high;
		};
		mux1 {
			groups = "GPIOC_4";
			function = "gpio_periphs";
			output-low;
		};
	};

	sd_clr_noall_pins: sd_clr_noall_pins {
		mux {
			groups = "GPIOC_0",
				   "GPIOC_1",
				   "GPIOC_4",
				   "GPIOC_5";
			function = "gpio_periphs";
			output-high;
		};
	};

	sd_1bit_pins: sd_1bit_pins {
		mux {
			groups = "sdcard_d0",
				 "sdcard_clk",
				 "sdcard_cmd";
			function = "sdcard";
			bias-pull-up;
			drive-strength-microamp = <3000>;
		};
	};

	sdcard_clk_gate_pins: sdcard_clk_gate_pins {
		mux {
			groups = "GPIOC_4";
			function = "gpio_periphs";
			bias-pull-down;
			drive-strength-microamp = <3000>;
		};
	};

	sd_iso7816_pins:sd_iso7816_pins {
		mux {
			groups = "iso7816_clk_h",
				"iso7816_data_h";
			function = "iso7816";
			input-enable;
			bias-pull-down;
		};
	};

	sdio_pins: sdio_pins {
		mux {
			groups = "sdio_d0",
				 "sdio_d1",
				 "sdio_d2",
				 "sdio_d3",
				 "sdio_clk",
				 "sdio_cmd";
			function = "sdio";
			bias-pull-up;
			drive-strength-microamp = <3000>;
		};
	};

	sdio_clk_gate_pins: sdio_clk_gate_pins {
		mux {
			groups = "GPIOX_4";
			function = "gpio_periphs";
			bias-pull-down;
			drive-strength-microamp = <3000>;
		};
	};

	hdmitx_hpd: hdmitx_hpd {
		mux {
			groups = "hdmitx_hpd_in";
			function = "hdmitx";
			bias-disable;
		};
	};

	hdmitx_hpd_gpio: hdmitx_hpd_gpio {
		mux {
			groups = "GPIOH_1";
			function = "gpio_periphs";
			bias-disable;
		};
	};

	hdmitx_ddc: hdmitx_ddc {
		mux {
			groups = "hdmitx_sda",
				"hdmitx_scl";
			function = "hdmitx";
			bias-disable;
			drive-strength = <3>;
		};
	};

	dtvdemod_if_agc_pins: dtvdemod_if_agc_pins {
		mux {
			groups = "dtv_a_if_agc_z10";
			function = "dtv";
		};
	};

	dtvdemod_if_agc2_pins: dtvdemod_if_agc2_pins {
		mux {
			groups = "dtv_b_if_agc";
			function = "dtv";
		};
	};

	dtvdemod_rf_agc_pins: dtvdemod_rf_agc_pins {
		mux {
			groups = "dtv_a_rf_agc";
			function = "dtv";
		};
	};

	diseqc_out: diseqc_out {
		mux {
			groups = "diseqc_out";
			function = "diseqc_out";
			bias-pull-down;
		};
	};

	diseqc_in: diseqc_in {
		mux {
			groups = "diseqc_in";
			function = "diseqc_in";
			bias-pull-down;
		};
	};

	eecec_a: ee_ceca {
		mux {
			groups = "ao_cec_a";
			function = "ao_cec_a";
		};
	};

	eecec_b: ee_cecb {
		mux {
			groups = "ao_cec_h";
			function = "ao_cec";
		};
	};

	jtag_a_pins: jtag_a_pin {
		mux {
			groups = "jtag_a_tdi",
				 "jtag_a_tdo",
				 "jtag_a_clk",
				 "jtag_a_tms";
			function = "jtag_a";
		};
	};

	jtag_b_pins: jtag_b_pin {
		mux {
			groups = "jtag_b_tdi",
				 "jtag_b_tdo",
				 "jtag_b_clk",
				 "jtag_b_tms";
			function = "jtag_b";
		};
	};

	pwm_c_pins1: pwm_c_pins1 {
		mux {
			groups = "pwm_c_e";
			function = "pwm_c";
		};
	};

	pwm_c_pins1_sleep: pwm_c_pins1_sleep {
		mux {
			groups = "GPIOE_0";
			function = "gpio_periphs";
			input-enable;
		};
	};

	pwm_d_pins1: pwm_d_pins1 {
		mux {
			groups = "pwm_d_e";
			function = "pwm_d";
		};
	};

	pwm_d_pins1_sleep: pwm_d_pins1_sleep {
		mux {
			groups = "GPIOE_1";
			function = "gpio_periphs";
			input-enable;
		};
	};

	pwm_e_pins1: pwm_e_pins1 {
		mux {
			groups = "pwm_e_e";
			function = "pwm_e";
		};
	};

	pwm_e_pins1_sleep: pwm_e_pins1_sleep {
		mux {
			groups = "GPIOE_2";
			function = "gpio_periphs";
			input-enable;
		};
	};

	pwm_f_pins1: pwm_f_pins1 {
		mux {
			groups = "pwm_f_e";
			function = "pwm_f";
		};
	};

	pwm_f_pins1_sleep: pwm_f_pins1_sleep {
		mux {
			groups = "GPIOE_3";
			function = "gpio_periphs";
			input-enable;
		};
	};

	pwm_g_pins1: pwm_g_pins1 {
		mux {
			groups = "pwm_g_e";
			function = "pwm_g";
		};
	};

	pwm_g_pins1_sleep: pwm_g_pins1_sleep {
		mux {
			groups = "GPIOE_4";
			function = "gpio_periphs";
			input-enable;
		};
	};

	pwm_h_pins1: pwm_h_pins1 {
		mux {
			groups = "pwm_h_e";
			function = "pwm_h";
		};
	};

	pwm_h_pins1_sleep: pwm_h_pins1_sleep {
		mux {
			groups = "GPIOE_5";
			function = "gpio_periphs";
			input-enable;
		};
	};

	pwm_i_pins1: pwm_i_pins1 {
		mux {
			groups = "pwm_i_e";
			function = "pwm_i";
		};
	};

	pwm_i_pins1_sleep: pwm_i_pins1_sleep {
		mux {
			groups = "GPIOE_6";
			function = "gpio_periphs";
			input-enable;
		};
	};

	pwm_j_pins1: pwm_j_pins1 {
		mux {
			groups = "pwm_j_e";
			function = "pwm_j";
		};
	};

	pwm_j_pins1_sleep: pwm_j_pins1_sleep {
		mux {
			groups = "GPIOE_7";
			function = "gpio_periphs";
			input-enable;
		};
	};

	pwm_k_pins1: pwm_k_pins1 {
		mux {
			groups = "pwm_k_d";
			function = "pwm_k";
		};
	};

	pwm_k_pins1_sleep: pwm_k_pins1_sleep {
		mux {
			groups = "GPIOD_3";
			function = "gpio_periphs";
			input-enable;
		};
	};

	pwm_k_pins2: pwm_k_pins2 {
		mux {
			groups = "pwm_k_x";
			function = "pwm_k";
		};
	};

	pwm_k_pins2_sleep: pwm_k_pins2_sleep {
		mux {
			groups = "GPIOX_11";
			function = "gpio_periphs";
			input-enable;
		};
	};

	pwm_k_pins3: pwm_k_pins3 {
		mux {
			groups = "pwm_k_dsi";
			function = "pwm_k";
		};
	};

	pwm_k_pins3_sleep: pwm_k_pins3_sleep {
		mux {
			groups = "GPIODSI_0";
			function = "gpio_periphs";
			input-enable;
		};
	};

	pwm_l_pins1: pwm_l_pins1 {
		mux {
			groups = "pwm_l_d";
			function = "pwm_l";
		};
	};

	pwm_l_pins1_sleep: pwm_l_pins1_sleep {
		mux {
			groups = "GPIOD_4";
			function = "gpio_periphs";
			input-enable;
		};
	};

	pwm_l_pins2: pwm_l_pins2 {
		mux {
			groups = "pwm_l_x";
			function = "pwm_l";
		};
	};

	pwm_l_pins2_sleep: pwm_l_pins2_sleep {
		mux {
			groups = "GPIOX_12";
			function = "gpio_periphs";
			input-enable;
		};
	};

	pwm_l_pins3: pwm_l_pins3 {
		mux {
			groups = "pwm_l_dsi";
			function = "pwm_l";
		};
	};

	pwm_l_pins3_sleep: pwm_l_pins3_sleep {
		mux {
			groups = "GPIODSI_1";
			function = "gpio_periphs";
			input-enable;
		};
	};

	pwm_m_pins1: pwm_m_pins1 {
		mux {
			groups = "pwm_m_d";
			function = "pwm_m";
		};
	};

	pwm_m_pins1_sleep: pwm_m_pins1_sleep {
		mux {
			groups = "GPIOD_5";
			function = "gpio_periphs";
			input-enable;
		};
	};

	pwm_m_pins2: pwm_m_pins2 {
		mux {
			groups = "pwm_m_x";
			function = "pwm_m";
		};
	};

	pwm_m_pins2_sleep: pwm_m_pins2_sleep {
		mux {
			groups = "GPIOX_13";
			function = "gpio_periphs";
			input-enable;
		};
	};

	pwm_m_pins3: pwm_m_pins3 {
		mux {
			groups = "pwm_m_dsi";
			function = "pwm_m";
		};
	};

	pwm_m_pins3_sleep: pwm_m_pins3_sleep {
		mux {
			groups = "GPIODSI_2";
			function = "gpio_periphs";
			input-enable;
		};
	};

	pwm_m_pins4: pwm_m_pins4 {
		mux {
			groups = "pwm_m_c";
			function = "pwm_m";
		};
	};

	pwm_m_pins4_sleep: pwm_m_pins4_sleep {
		mux {
			groups = "GPIOC_2";
			function = "gpio_periphs";
			input-enable;
		};
	};

	pwm_n_pins1: pwm_n_pins1 {
		mux {
			groups = "pwm_n_d";
			function = "pwm_n";
		};
	};

	pwm_n_pins1_sleep: pwm_n_pins1_sleep {
		mux {
			groups = "GPIOD_6";
			function = "gpio_periphs";
			input-enable;
		};
	};

	pwm_n_pins2: pwm_n_pins2 {
		mux {
			groups = "pwm_n_x";
			function = "pwm_n";
		};
	};

	pwm_n_pins2_sleep: pwm_n_pins2_sleep {
		mux {
			groups = "GPIOX_0";
			function = "gpio_periphs";
			input-enable;
		};
	};

	pwm_n_pins3: pwm_n_pins3 {
		mux {
			groups = "pwm_n_dsi";
			function = "pwm_n";
		};
	};

	pwm_n_pins3_sleep: pwm_n_pins3_sleep {
		mux {
			groups = "GPIODSI_3";
			function = "gpio_periphs";
			input-enable;
		};
	};

	pwm_n_pins4: pwm_n_pins4 {
		mux {
			groups = "pwm_n_c";
			function = "pwm_n";
		};
	};

	pwm_n_pins4_sleep: pwm_n_pins4_sleep {
		mux {
			groups = "GPIOC_3";
			function = "gpio_periphs";
			input-enable;
		};
	};

	pwm_o_pins1: pwm_o_pins1 {
		mux {
			groups = "pwm_o_d";
			function = "pwm_o";
		};
	};

	pwm_o_pins1_sleep: pwm_o_pins1_sleep {
		mux {
			groups = "GPIOD_7";
			function = "gpio_periphs";
			input-enable;
		};
	};

	pwm_o_pins2: pwm_o_pins2 {
		mux {
			groups = "pwm_o_x";
			function = "pwm_o";
		};
	};

	pwm_o_pins2_sleep: pwm_o_pins2_sleep {
		mux {
			groups = "GPIOX_1";
			function = "gpio_periphs";
			input-enable;
		};
	};

	pwm_o_pins3: pwm_o_pins3 {
		mux {
			groups = "pwm_o_dsi";
			function = "pwm_o";
		};
	};

	pwm_o_pins3_sleep: pwm_o_pins3_sleep {
		mux {
			groups = "GPIODSI_3";
			function = "gpio_periphs";
			input-enable;
		};
	};

	pwm_o_pins4: pwm_o_pins4 {
		mux {
			groups = "pwm_o_c";
			function = "pwm_o";
		};
	};

	pwm_o_pins4_sleep: pwm_o_pins4_sleep {
		mux {
			groups = "GPIOC_4";
			function = "gpio_periphs";
			input-enable;
		};
	};

	pwm_o_pins5: pwm_o_pins5 {
		mux {
			groups = "pwm_o_b";
			function = "pwm_o";
		};
	};

	pwm_o_pins5_sleep: pwm_o_pins5_sleep {
		mux {
			groups = "GPIOB_4";
			function = "gpio_periphs";
			input-enable;
		};
	};

	pwm_p_pins1: pwm_p_pins1 {
		mux {
			groups = "pwm_p_b";
			function = "pwm_p";
		};
	};

	pwm_p_pins1_sleep: pwm_p_pins1_sleep {
		mux {
			groups = "GPIOB_5";
			function = "gpio_periphs";
			input-enable;
		};
	};

	pwm_p_pins2: pwm_p_pins2 {
		mux {
			groups = "pwm_p_c";
			function = "pwm_p";
		};
	};

	pwm_p_pins2_sleep: pwm_p_pins2_sleep {
		mux {
			groups = "GPIOC_5";
			function = "gpio_periphs";
			input-enable;
		};
	};

	pwm_p_pins3: pwm_p_pins3 {
		mux {
			groups = "pwm_p_d";
			function = "pwm_p";
		};
	};

	pwm_p_pins3_sleep: pwm_p_pins3_sleep {
		mux {
			groups = "GPIOD_8";
			function = "gpio_periphs";
			input-enable;
		};
	};

	pwm_p_pins4: pwm_p_pins4 {
		mux {
			groups = "pwm_p_dsi";
			function = "pwm_p";
		};
	};

	pwm_p_pins4_sleep: pwm_p_pins4_sleep {
		mux {
			groups = "GPIODSI_5";
			function = "gpio_periphs";
			input-enable;
		};
	};

	pwm_q_pins1: pwm_q_pins1 {
		mux {
			groups = "pwm_q_b";
			function = "pwm_q";
		};
	};

	pwm_q_pins1_sleep: pwm_q_pins1_sleep {
		mux {
			groups = "GPIOB_6";
			function = "gpio_periphs";
			input-enable;
		};
	};

	pwm_q_pins2: pwm_q_pins2 {
		mux {
			groups = "pwm_q_c";
			function = "pwm_q";
		};
	};

	pwm_q_pins2_sleep: pwm_q_pins2_sleep {
		mux {
			groups = "GPIOC_6";
			function = "gpio_periphs";
			input-enable;
		};
	};

	pwm_q_pins3: pwm_q_pins3 {
		mux {
			groups = "pwm_q_d";
			function = "pwm_q";
		};
	};

	pwm_q_pins3_sleep: pwm_q_pins3_sleep {
		mux {
			groups = "GPIOD_9";
			function = "gpio_periphs";
			input-enable;
		};
	};

	pwm_q_pins4: pwm_q_pins4 {
		mux {
			groups = "pwm_q_dsi";
			function = "pwm_q";
		};
	};

	pwm_q_pins4_sleep: pwm_q_pins4_sleep {
		mux {
			groups = "GPIODSI_6";
			function = "gpio_periphs";
			input-enable;
		};
	};

	pwm_q_pins5: pwm_q_pins5 {
		mux {
			groups = "pwm_q_x";
			function = "pwm_q";
		};
	};

	pwm_q_pins5_sleep: pwm_q_pins5_sleep {
		mux {
			groups = "GPIOX_3";
			function = "gpio_periphs";
			input-enable;
		};
	};

	pwm_r_pins1: pwm_r_pins1 {
		mux {
			groups = "pwm_r_b";
			function = "pwm_r";
		};
	};

	pwm_r_pins1_sleep: pwm_r_pins1_sleep {
		mux {
			groups = "GPIOB_7";
			function = "gpio_periphs";
			input-enable;
		};
	};

	pwm_r_pins2: pwm_r_pins2 {
		mux {
			groups = "pwm_r_d";
			function = "pwm_r";
		};
	};

	pwm_r_pins2_sleep: pwm_r_pins2_sleep {
		mux {
			groups = "GPIOD_10";
			function = "gpio_periphs";
			input-enable;
		};
	};

	pwm_r_pins3: pwm_r_pins3 {
		mux {
			groups = "pwm_r_x";
			function = "pwm_r";
		};
	};

	pwm_r_pins3_sleep: pwm_r_pins3_sleep {
		mux {
			groups = "GPIOX_4";
			function = "gpio_periphs";
			input-enable;
		};
	};

	pwm_r_pins4: pwm_r_pins4 {
		mux {
			groups = "pwm_r_dsi";
			function = "pwm_r";
		};
	};

	pwm_r_pins4_sleep: pwm_r_pins4_sleep {
		mux {
			groups = "GPIODSI_7";
			function = "gpio_periphs";
			input-enable;
		};
	};

	pwm_s_pins1: pwm_s_pins1 {
		mux {
			groups = "pwm_s_b";
			function = "pwm_s";
		};
	};

	pwm_s_pins1_sleep: pwm_s_pins1_sleep {
		mux {
			groups = "GPIOB_8";
			function = "gpio_periphs";
			input-enable;
		};
	};

	pwm_s_pins2: pwm_s_pins2 {
		mux {
			groups = "pwm_s_c";
			function = "pwm_s";
		};
	};

	pwm_s_pins2_sleep: pwm_s_pins2_sleep {
		mux {
			groups = "GPIOC_0";
			function = "gpio_periphs";
			input-enable;
		};
	};

	pwm_s_pins3: pwm_s_pins3 {
		mux {
			groups = "pwm_s_d";
			function = "pwm_s";
		};
	};

	pwm_s_pins3_sleep: pwm_s_pins3_sleep {
		mux {
			groups = "GPIOD_11";
			function = "gpio_periphs";
			input-enable;
		};
	};

	pwm_s_pins4: pwm_s_pins4 {
		mux {
			groups = "pwm_s_x";
			function = "pwm_s";
		};
	};

	pwm_s_pins4_sleep: pwm_s_pins4_sleep {
		mux {
			groups = "GPIOX_5";
			function = "gpio_periphs";
			input-enable;
		};
	};

	pwm_s_pins5: pwm_s_pins5 {
		mux {
			groups = "pwm_s_dsi";
			function = "pwm_s";
		};
	};

	pwm_s_pins5_sleep: pwm_s_pins5_sleep {
		mux {
			groups = "GPIODSI_8";
			function = "gpio_periphs";
			input-enable;
		};
	};

	pwm_t_pins1: pwm_t_pins1 {
		mux {
			groups = "pwm_t_b";
			function = "pwm_t";
		};
	};

	pwm_t_pins1_sleep: pwm_t_pins1_sleep {
		mux {
			groups = "GPIOB_9";
			function = "gpio_periphs";
			input-enable;
		};
	};

	pwm_t_pins2: pwm_t_pins2 {
		mux {
			groups = "pwm_t_c";
			function = "pwm_t";
		};
	};

	pwm_t_pins2_sleep: pwm_t_pins2_sleep {
		mux {
			groups = "GPIOC_1";
			function = "gpio_periphs";
			input-enable;
		};
	};

	pwm_t_pins3: pwm_t_pins3 {
		mux {
			groups = "pwm_t_d";
			function = "pwm_t";
		};
	};

	pwm_t_pins3_sleep: pwm_t_pins3_sleep {
		mux {
			groups = "GPIOD_2";
			function = "gpio_periphs";
			input-enable;
		};
	};

	pwm_t_pins4: pwm_t_pins4 {
		mux {
			groups = "pwm_t_x";
			function = "pwm_t";
		};
	};

	pwm_t_pins4_sleep: pwm_t_pins4_sleep {
		mux {
			groups = "GPIOX_10";
			function = "gpio_periphs";
			input-enable;
		};
	};

	pwm_t_pins5: pwm_t_pins5 {
		mux {
			groups = "pwm_t_dsi";
			function = "pwm_t";
		};
	};

	pwm_t_pins5_sleep: pwm_t_pins5_sleep {
		mux {
			groups = "GPIODSI_9";
			function = "gpio_periphs";
			input-enable;
		};
	};

	spisg_b_pins_p: spisg_b_pins_p {
		mux {
			 /* GPIOP_5/6/7/4 */
			groups = "spi1_mosi_p",
				 "spi1_miso_p",
				 "spi1_ss0_p",
				 "spi1_sclk_p";
			function = "spi1";
			drive-strength-microamp = <3000>;
		};
	};

	spisg_b_pins_b: spisg_b_pins_b {
		mux {
			 /* GPIOB_6/7/4/8/9/5 */
			groups = "spi1_mosi_b",
				 "spi1_miso_b",
				 "spi1_ss0_b",
				 "spi1_ss1_b",
				 "spi1_ss2_b",
				 "spi1_sclk_b";
			function = "spi1";
			drive-strength-microamp = <3000>;
		};
	};

	spisg_b_pins_c: spisg_b_pins_c {
		mux {
			 /* GPIOC_0/1/3/4/5/2 */
			groups = "spi1_mosi_c",
				 "spi1_miso_c",
				 "spi1_ss0_c",
				 "spi1_ss1_c",
				 "spi1_ss2_c",
				 "spi1_sclk_c";
			function = "spi1";
			drive-strength-microamp = <3000>;
		};
	};

	spisg_b_pins_d: spisg_b_pins_d {
		mux {
			 /* GPIOD_5/4/7/6 */
			groups = "spi1_mosi_d",
				 "spi1_miso_d",
				 "spi1_ss1_d",
				 "spi1_sclk_d";
			function = "spi1";
			drive-strength-microamp = <3000>;
		};
	};

	spisg_b_pins_x: spisg_b_pins_x {
		mux {
			 /* GPIOX_12/13/10/11 */
			groups = "spi1_mosi_x",
				 "spi1_miso_x",
				 "spi1_ss0_x",
				 "spi1_sclk_x";
			function = "spi1";
			drive-strength-microamp = <3000>;
		};
	};

	spisg_c_pins_d: spisg_c_pins_d {
		mux {
			 /* GPIOD_0/1/3/2 */
			groups = "spi2_mosi_d",
				 "spi2_miso_d",
				 "spi2_ss0_d",
				 "spi2_sclk_d";
			function = "spi2";
			drive-strength-microamp = <3000>;
		};
	};

	spisg_c_pins_x: spisg_c_pins_x {
		mux {
			 /* GPIOX_7/8/9/6 */
			groups = "spi2_mosi_x",
				 "spi2_miso_x",
				 "spi2_ss0_x",
				 "spi2_sclk_x";
			function = "spi2";
			drive-strength-microamp = <3000>;
		};
	};

	spisg_d_pins_x: spisg_d_pins_x {
		mux {
			 /* GPIOX_1/2/3/4/0 */
			groups = "spi3_mosi",
				 "spi3_miso",
				 "spi3_ss0",
				 "spi3_ss1",
				 "spi3_sclk";
			function = "spi3";
			drive-strength-microamp = <3000>;
		};
	};

	spifc_pins:spifc_pins {
		mux {
			groups = "spif_hold",
				 "spif_mo",
				 "spif_mi",
				 "spif_clk",
				 "spif_wp",
				 "spif_cs";
			function = "spif";
			drive-strength-microamp = <3000>;
		};
	};

	irblaster_pin_f:irblaster_pin_f {
		mux {
			groups = "ir_remote_out_f";
			function = "ir_remote";
		};
	};

	irblaster_pin_h:irblaster_pin_h {
		mux {
			groups = "ir_remote_out_h";
			function = "ir_remote";
		};
	};

	irblaster_pin_z:irblaster_pin_z {
		mux {
			groups = "ir_remote_out_z";
			function = "ir_remote";
		};
	};

	irblaster_pin_a:irblaster_pin_a {
		mux {
			groups = "ir_remote_out_a";
			function = "ir_remote";
		};
	};

	spdifin: spdifin {
		mux {/* GPIOH_5 */
			groups = "spdif_in";
			function = "spdif_in";
		};
	};
};

&gpu{
	status = "disabled";
	operating-points-v2 = <&gpu_opp_table>;
	reg =   <0x0 0xFD000000 0x0 0x800000>, /*mali APB bus base address*/
		<0x0 0xFE002000 0x0 0x01000>; /*reset register*/

	interrupts = <GIC_SPI 145 IRQ_TYPE_LEVEL_HIGH>,
		     <GIC_SPI 146 IRQ_TYPE_LEVEL_HIGH>,
		     <GIC_SPI 144 IRQ_TYPE_LEVEL_HIGH>;
	interrupt-names = "GPU", "MMU", "JOB";

	/* Protected memory allocator default not available*/
	//protected-memory-allocator = <&gpu_protected_memory_allocator>;

	num_of_pp = <1>;
	system-coherency = <31>;
	//clocks = <&clkc CLKID_MALI>,
	//	 <&clkc CLKID_MALI_STACK>;
	//clock-names = "gpu_mux", "gpu_stack";

	/*
	 * Mali clocking is provided by two identical clock paths
	 * MALI_0 and MALI_1 muxed to a single clock by a glitch
	 * free mux to safely change frequency while running.
	 */
	//assigned-clocks = <&clkc CLKID_MALI_0_MUX>,
	//		  <&clkc CLKID_MALI_0>,
	//		  <&clkc CLKID_MALI>,
	//		  <&clkc CLKID_MALI_STACK_0_MUX>,
	//		  <&clkc CLKID_MALI_STACK_0>,
	//		  <&clkc CLKID_MALI_STACK>, /* Glitch free mux */
	//		  <&scmi_clk CLKID_GP1_PLL>;
	//assigned-clock-parents = <&clkc CLKID_FCLK_DIV5>,
	//			 <0>, /* Do Nothing */
	//			 <&clkc CLKID_MALI_0>,
	//			 <&clkc CLKID_FCLK_DIV5>,
	//			 <0>,
	//			 <&clkc CLKID_MALI_STACK_0>,
	//			 <0>;
	//assigned-clock-rates = <0>, /* Do Nothing */
	//		       <400000000>,
	//		       <0>,
	//		       <0>,
	//		       <400000000>,
	//		       <0>, /* Do Nothing */
	//		       <996000000>;

	tbl = <&dvfs400_cfg>;//bringup s6 use fix clock 400M

};

#include "mesonc5_cpufreq.dtsi"
